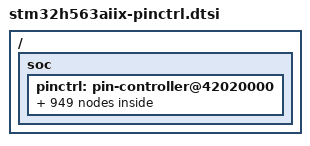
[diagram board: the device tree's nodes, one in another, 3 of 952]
/*
 * NOTE: Autogenerated file using genpinctrl.py
 *
 * SPDX-License-Identifier: Apache-2.0
 */

#include <zephyr/dt-bindings/pinctrl/stm32-pinctrl.h>

/ {
	soc {
		pinctrl: pin-controller@42020000 {

			/* ADC_IN / ADC_INN / ADC_INP */

			/omit-if-no-ref/ adc1_inn1_pa0: adc1_inn1_pa0 {
				pinmux = <STM32_PINMUX('A', 0, ANALOG)>;
			};

			/omit-if-no-ref/ adc1_inp0_pa0: adc1_inp0_pa0 {
				pinmux = <STM32_PINMUX('A', 0, ANALOG)>;
			};

			/omit-if-no-ref/ adc1_inp1_pa1: adc1_inp1_pa1 {
				pinmux = <STM32_PINMUX('A', 1, ANALOG)>;
			};

			/omit-if-no-ref/ adc1_inp14_pa2: adc1_inp14_pa2 {
				pinmux = <STM32_PINMUX('A', 2, ANALOG)>;
			};

			/omit-if-no-ref/ adc1_inp15_pa3: adc1_inp15_pa3 {
				pinmux = <STM32_PINMUX('A', 3, ANALOG)>;
			};

			/omit-if-no-ref/ adc1_inp18_pa4: adc1_inp18_pa4 {
				pinmux = <STM32_PINMUX('A', 4, ANALOG)>;
			};

			/omit-if-no-ref/ adc1_inn18_pa5: adc1_inn18_pa5 {
				pinmux = <STM32_PINMUX('A', 5, ANALOG)>;
			};

			/omit-if-no-ref/ adc1_inp19_pa5: adc1_inp19_pa5 {
				pinmux = <STM32_PINMUX('A', 5, ANALOG)>;
			};

			/omit-if-no-ref/ adc1_inp3_pa6: adc1_inp3_pa6 {
				pinmux = <STM32_PINMUX('A', 6, ANALOG)>;
			};

			/omit-if-no-ref/ adc1_inn3_pa7: adc1_inn3_pa7 {
				pinmux = <STM32_PINMUX('A', 7, ANALOG)>;
			};

			/omit-if-no-ref/ adc1_inp7_pa7: adc1_inp7_pa7 {
				pinmux = <STM32_PINMUX('A', 7, ANALOG)>;
			};

			/omit-if-no-ref/ adc1_inn5_pb0: adc1_inn5_pb0 {
				pinmux = <STM32_PINMUX('B', 0, ANALOG)>;
			};

			/omit-if-no-ref/ adc1_inp9_pb0: adc1_inp9_pb0 {
				pinmux = <STM32_PINMUX('B', 0, ANALOG)>;
			};

			/omit-if-no-ref/ adc1_inp5_pb1: adc1_inp5_pb1 {
				pinmux = <STM32_PINMUX('B', 1, ANALOG)>;
			};

			/omit-if-no-ref/ adc1_inp10_pc0: adc1_inp10_pc0 {
				pinmux = <STM32_PINMUX('C', 0, ANALOG)>;
			};

			/omit-if-no-ref/ adc1_inn10_pc1: adc1_inn10_pc1 {
				pinmux = <STM32_PINMUX('C', 1, ANALOG)>;
			};

			/omit-if-no-ref/ adc1_inp11_pc1: adc1_inp11_pc1 {
				pinmux = <STM32_PINMUX('C', 1, ANALOG)>;
			};

			/omit-if-no-ref/ adc1_inn11_pc2: adc1_inn11_pc2 {
				pinmux = <STM32_PINMUX('C', 2, ANALOG)>;
			};

			/omit-if-no-ref/ adc1_inp12_pc2: adc1_inp12_pc2 {
				pinmux = <STM32_PINMUX('C', 2, ANALOG)>;
			};

			/omit-if-no-ref/ adc1_inn12_pc3: adc1_inn12_pc3 {
				pinmux = <STM32_PINMUX('C', 3, ANALOG)>;
			};

			/omit-if-no-ref/ adc1_inp13_pc3: adc1_inp13_pc3 {
				pinmux = <STM32_PINMUX('C', 3, ANALOG)>;
			};

			/omit-if-no-ref/ adc1_inp4_pc4: adc1_inp4_pc4 {
				pinmux = <STM32_PINMUX('C', 4, ANALOG)>;
			};

			/omit-if-no-ref/ adc1_inn4_pc5: adc1_inn4_pc5 {
				pinmux = <STM32_PINMUX('C', 5, ANALOG)>;
			};

			/omit-if-no-ref/ adc1_inp8_pc5: adc1_inp8_pc5 {
				pinmux = <STM32_PINMUX('C', 5, ANALOG)>;
			};

			/omit-if-no-ref/ adc1_inp2_pf11: adc1_inp2_pf11 {
				pinmux = <STM32_PINMUX('F', 11, ANALOG)>;
			};

			/omit-if-no-ref/ adc1_inn2_pf12: adc1_inn2_pf12 {
				pinmux = <STM32_PINMUX('F', 12, ANALOG)>;
			};

			/omit-if-no-ref/ adc1_inp6_pf12: adc1_inp6_pf12 {
				pinmux = <STM32_PINMUX('F', 12, ANALOG)>;
			};

			/omit-if-no-ref/ adc2_inn1_pa0: adc2_inn1_pa0 {
				pinmux = <STM32_PINMUX('A', 0, ANALOG)>;
			};

			/omit-if-no-ref/ adc2_inp0_pa0: adc2_inp0_pa0 {
				pinmux = <STM32_PINMUX('A', 0, ANALOG)>;
			};

			/omit-if-no-ref/ adc2_inp1_pa1: adc2_inp1_pa1 {
				pinmux = <STM32_PINMUX('A', 1, ANALOG)>;
			};

			/omit-if-no-ref/ adc2_inp14_pa2: adc2_inp14_pa2 {
				pinmux = <STM32_PINMUX('A', 2, ANALOG)>;
			};

			/omit-if-no-ref/ adc2_inp15_pa3: adc2_inp15_pa3 {
				pinmux = <STM32_PINMUX('A', 3, ANALOG)>;
			};

			/omit-if-no-ref/ adc2_inp18_pa4: adc2_inp18_pa4 {
				pinmux = <STM32_PINMUX('A', 4, ANALOG)>;
			};

			/omit-if-no-ref/ adc2_inn18_pa5: adc2_inn18_pa5 {
				pinmux = <STM32_PINMUX('A', 5, ANALOG)>;
			};

			/omit-if-no-ref/ adc2_inp19_pa5: adc2_inp19_pa5 {
				pinmux = <STM32_PINMUX('A', 5, ANALOG)>;
			};

			/omit-if-no-ref/ adc2_inp3_pa6: adc2_inp3_pa6 {
				pinmux = <STM32_PINMUX('A', 6, ANALOG)>;
			};

			/omit-if-no-ref/ adc2_inn3_pa7: adc2_inn3_pa7 {
				pinmux = <STM32_PINMUX('A', 7, ANALOG)>;
			};

			/omit-if-no-ref/ adc2_inp7_pa7: adc2_inp7_pa7 {
				pinmux = <STM32_PINMUX('A', 7, ANALOG)>;
			};

			/omit-if-no-ref/ adc2_inn5_pb0: adc2_inn5_pb0 {
				pinmux = <STM32_PINMUX('B', 0, ANALOG)>;
			};

			/omit-if-no-ref/ adc2_inp9_pb0: adc2_inp9_pb0 {
				pinmux = <STM32_PINMUX('B', 0, ANALOG)>;
			};

			/omit-if-no-ref/ adc2_inp5_pb1: adc2_inp5_pb1 {
				pinmux = <STM32_PINMUX('B', 1, ANALOG)>;
			};

			/omit-if-no-ref/ adc2_inp10_pc0: adc2_inp10_pc0 {
				pinmux = <STM32_PINMUX('C', 0, ANALOG)>;
			};

			/omit-if-no-ref/ adc2_inn10_pc1: adc2_inn10_pc1 {
				pinmux = <STM32_PINMUX('C', 1, ANALOG)>;
			};

			/omit-if-no-ref/ adc2_inp11_pc1: adc2_inp11_pc1 {
				pinmux = <STM32_PINMUX('C', 1, ANALOG)>;
			};

			/omit-if-no-ref/ adc2_inn11_pc2: adc2_inn11_pc2 {
				pinmux = <STM32_PINMUX('C', 2, ANALOG)>;
			};

			/omit-if-no-ref/ adc2_inp12_pc2: adc2_inp12_pc2 {
				pinmux = <STM32_PINMUX('C', 2, ANALOG)>;
			};

			/omit-if-no-ref/ adc2_inn12_pc3: adc2_inn12_pc3 {
				pinmux = <STM32_PINMUX('C', 3, ANALOG)>;
			};

			/omit-if-no-ref/ adc2_inp13_pc3: adc2_inp13_pc3 {
				pinmux = <STM32_PINMUX('C', 3, ANALOG)>;
			};

			/omit-if-no-ref/ adc2_inp4_pc4: adc2_inp4_pc4 {
				pinmux = <STM32_PINMUX('C', 4, ANALOG)>;
			};

			/omit-if-no-ref/ adc2_inn4_pc5: adc2_inn4_pc5 {
				pinmux = <STM32_PINMUX('C', 5, ANALOG)>;
			};

			/omit-if-no-ref/ adc2_inp8_pc5: adc2_inp8_pc5 {
				pinmux = <STM32_PINMUX('C', 5, ANALOG)>;
			};

			/omit-if-no-ref/ adc2_inp2_pf13: adc2_inp2_pf13 {
				pinmux = <STM32_PINMUX('F', 13, ANALOG)>;
			};

			/omit-if-no-ref/ adc2_inn2_pf14: adc2_inn2_pf14 {
				pinmux = <STM32_PINMUX('F', 14, ANALOG)>;
			};

			/omit-if-no-ref/ adc2_inp6_pf14: adc2_inp6_pf14 {
				pinmux = <STM32_PINMUX('F', 14, ANALOG)>;
			};

			/* Analog */

			/omit-if-no-ref/ analog_pa0: analog_pa0 {
				pinmux = <STM32_PINMUX('A', 0, ANALOG)>;
			};

			/omit-if-no-ref/ analog_pa1: analog_pa1 {
				pinmux = <STM32_PINMUX('A', 1, ANALOG)>;
			};

			/omit-if-no-ref/ analog_pa2: analog_pa2 {
				pinmux = <STM32_PINMUX('A', 2, ANALOG)>;
			};

			/omit-if-no-ref/ analog_pa3: analog_pa3 {
				pinmux = <STM32_PINMUX('A', 3, ANALOG)>;
			};

			/omit-if-no-ref/ analog_pa4: analog_pa4 {
				pinmux = <STM32_PINMUX('A', 4, ANALOG)>;
			};

			/omit-if-no-ref/ analog_pa5: analog_pa5 {
				pinmux = <STM32_PINMUX('A', 5, ANALOG)>;
			};

			/omit-if-no-ref/ analog_pa6: analog_pa6 {
				pinmux = <STM32_PINMUX('A', 6, ANALOG)>;
			};

			/omit-if-no-ref/ analog_pa7: analog_pa7 {
				pinmux = <STM32_PINMUX('A', 7, ANALOG)>;
			};

			/omit-if-no-ref/ analog_pa8: analog_pa8 {
				pinmux = <STM32_PINMUX('A', 8, ANALOG)>;
			};

			/omit-if-no-ref/ analog_pa9: analog_pa9 {
				pinmux = <STM32_PINMUX('A', 9, ANALOG)>;
			};

			/omit-if-no-ref/ analog_pa10: analog_pa10 {
				pinmux = <STM32_PINMUX('A', 10, ANALOG)>;
			};

			/omit-if-no-ref/ analog_pa11: analog_pa11 {
				pinmux = <STM32_PINMUX('A', 11, ANALOG)>;
			};

			/omit-if-no-ref/ analog_pa12: analog_pa12 {
				pinmux = <STM32_PINMUX('A', 12, ANALOG)>;
			};

			/omit-if-no-ref/ analog_pa13: analog_pa13 {
				pinmux = <STM32_PINMUX('A', 13, ANALOG)>;
			};

			/omit-if-no-ref/ analog_pa14: analog_pa14 {
				pinmux = <STM32_PINMUX('A', 14, ANALOG)>;
			};

			/omit-if-no-ref/ analog_pa15: analog_pa15 {
				pinmux = <STM32_PINMUX('A', 15, ANALOG)>;
			};

			/omit-if-no-ref/ analog_pb0: analog_pb0 {
				pinmux = <STM32_PINMUX('B', 0, ANALOG)>;
			};

			/omit-if-no-ref/ analog_pb1: analog_pb1 {
				pinmux = <STM32_PINMUX('B', 1, ANALOG)>;
			};

			/omit-if-no-ref/ analog_pb2: analog_pb2 {
				pinmux = <STM32_PINMUX('B', 2, ANALOG)>;
			};

			/omit-if-no-ref/ analog_pb3: analog_pb3 {
				pinmux = <STM32_PINMUX('B', 3, ANALOG)>;
			};

			/omit-if-no-ref/ analog_pb4: analog_pb4 {
				pinmux = <STM32_PINMUX('B', 4, ANALOG)>;
			};

			/omit-if-no-ref/ analog_pb5: analog_pb5 {
				pinmux = <STM32_PINMUX('B', 5, ANALOG)>;
			};

			/omit-if-no-ref/ analog_pb6: analog_pb6 {
				pinmux = <STM32_PINMUX('B', 6, ANALOG)>;
			};

			/omit-if-no-ref/ analog_pb7: analog_pb7 {
				pinmux = <STM32_PINMUX('B', 7, ANALOG)>;
			};

			/omit-if-no-ref/ analog_pb8: analog_pb8 {
				pinmux = <STM32_PINMUX('B', 8, ANALOG)>;
			};

			/omit-if-no-ref/ analog_pb9: analog_pb9 {
				pinmux = <STM32_PINMUX('B', 9, ANALOG)>;
			};

			/omit-if-no-ref/ analog_pb10: analog_pb10 {
				pinmux = <STM32_PINMUX('B', 10, ANALOG)>;
			};

			/omit-if-no-ref/ analog_pb11: analog_pb11 {
				pinmux = <STM32_PINMUX('B', 11, ANALOG)>;
			};

			/omit-if-no-ref/ analog_pb12: analog_pb12 {
				pinmux = <STM32_PINMUX('B', 12, ANALOG)>;
			};

			/omit-if-no-ref/ analog_pb13: analog_pb13 {
				pinmux = <STM32_PINMUX('B', 13, ANALOG)>;
			};

			/omit-if-no-ref/ analog_pb14: analog_pb14 {
				pinmux = <STM32_PINMUX('B', 14, ANALOG)>;
			};

			/omit-if-no-ref/ analog_pb15: analog_pb15 {
				pinmux = <STM32_PINMUX('B', 15, ANALOG)>;
			};

			/omit-if-no-ref/ analog_pc0: analog_pc0 {
				pinmux = <STM32_PINMUX('C', 0, ANALOG)>;
			};

			/omit-if-no-ref/ analog_pc1: analog_pc1 {
				pinmux = <STM32_PINMUX('C', 1, ANALOG)>;
			};

			/omit-if-no-ref/ analog_pc2: analog_pc2 {
				pinmux = <STM32_PINMUX('C', 2, ANALOG)>;
			};

			/omit-if-no-ref/ analog_pc3: analog_pc3 {
				pinmux = <STM32_PINMUX('C', 3, ANALOG)>;
			};

			/omit-if-no-ref/ analog_pc4: analog_pc4 {
				pinmux = <STM32_PINMUX('C', 4, ANALOG)>;
			};

			/omit-if-no-ref/ analog_pc5: analog_pc5 {
				pinmux = <STM32_PINMUX('C', 5, ANALOG)>;
			};

			/omit-if-no-ref/ analog_pc6: analog_pc6 {
				pinmux = <STM32_PINMUX('C', 6, ANALOG)>;
			};

			/omit-if-no-ref/ analog_pc7: analog_pc7 {
				pinmux = <STM32_PINMUX('C', 7, ANALOG)>;
			};

			/omit-if-no-ref/ analog_pc8: analog_pc8 {
				pinmux = <STM32_PINMUX('C', 8, ANALOG)>;
			};

			/omit-if-no-ref/ analog_pc9: analog_pc9 {
				pinmux = <STM32_PINMUX('C', 9, ANALOG)>;
			};

			/omit-if-no-ref/ analog_pc10: analog_pc10 {
				pinmux = <STM32_PINMUX('C', 10, ANALOG)>;
			};

			/omit-if-no-ref/ analog_pc11: analog_pc11 {
				pinmux = <STM32_PINMUX('C', 11, ANALOG)>;
			};

			/omit-if-no-ref/ analog_pc12: analog_pc12 {
				pinmux = <STM32_PINMUX('C', 12, ANALOG)>;
			};

			/omit-if-no-ref/ analog_pc13: analog_pc13 {
				pinmux = <STM32_PINMUX('C', 13, ANALOG)>;
			};

			/omit-if-no-ref/ analog_pc14: analog_pc14 {
				pinmux = <STM32_PINMUX('C', 14, ANALOG)>;
			};

			/omit-if-no-ref/ analog_pc15: analog_pc15 {
				pinmux = <STM32_PINMUX('C', 15, ANALOG)>;
			};

			/omit-if-no-ref/ analog_pd0: analog_pd0 {
				pinmux = <STM32_PINMUX('D', 0, ANALOG)>;
			};

			/omit-if-no-ref/ analog_pd1: analog_pd1 {
				pinmux = <STM32_PINMUX('D', 1, ANALOG)>;
			};

			/omit-if-no-ref/ analog_pd2: analog_pd2 {
				pinmux = <STM32_PINMUX('D', 2, ANALOG)>;
			};

			/omit-if-no-ref/ analog_pd3: analog_pd3 {
				pinmux = <STM32_PINMUX('D', 3, ANALOG)>;
			};

			/omit-if-no-ref/ analog_pd4: analog_pd4 {
				pinmux = <STM32_PINMUX('D', 4, ANALOG)>;
			};

			/omit-if-no-ref/ analog_pd5: analog_pd5 {
				pinmux = <STM32_PINMUX('D', 5, ANALOG)>;
			};

			/omit-if-no-ref/ analog_pd6: analog_pd6 {
				pinmux = <STM32_PINMUX('D', 6, ANALOG)>;
			};

			/omit-if-no-ref/ analog_pd7: analog_pd7 {
				pinmux = <STM32_PINMUX('D', 7, ANALOG)>;
			};

			/omit-if-no-ref/ analog_pd8: analog_pd8 {
				pinmux = <STM32_PINMUX('D', 8, ANALOG)>;
			};

			/omit-if-no-ref/ analog_pd9: analog_pd9 {
				pinmux = <STM32_PINMUX('D', 9, ANALOG)>;
			};

			/omit-if-no-ref/ analog_pd10: analog_pd10 {
				pinmux = <STM32_PINMUX('D', 10, ANALOG)>;
			};

			/omit-if-no-ref/ analog_pd11: analog_pd11 {
				pinmux = <STM32_PINMUX('D', 11, ANALOG)>;
			};

			/omit-if-no-ref/ analog_pd12: analog_pd12 {
				pinmux = <STM32_PINMUX('D', 12, ANALOG)>;
			};

			/omit-if-no-ref/ analog_pd13: analog_pd13 {
				pinmux = <STM32_PINMUX('D', 13, ANALOG)>;
			};

			/omit-if-no-ref/ analog_pd14: analog_pd14 {
				pinmux = <STM32_PINMUX('D', 14, ANALOG)>;
			};

			/omit-if-no-ref/ analog_pd15: analog_pd15 {
				pinmux = <STM32_PINMUX('D', 15, ANALOG)>;
			};

			/omit-if-no-ref/ analog_pe0: analog_pe0 {
				pinmux = <STM32_PINMUX('E', 0, ANALOG)>;
			};

			/omit-if-no-ref/ analog_pe1: analog_pe1 {
				pinmux = <STM32_PINMUX('E', 1, ANALOG)>;
			};

			/omit-if-no-ref/ analog_pe2: analog_pe2 {
				pinmux = <STM32_PINMUX('E', 2, ANALOG)>;
			};

			/omit-if-no-ref/ analog_pe3: analog_pe3 {
				pinmux = <STM32_PINMUX('E', 3, ANALOG)>;
			};

			/omit-if-no-ref/ analog_pe4: analog_pe4 {
				pinmux = <STM32_PINMUX('E', 4, ANALOG)>;
			};

			/omit-if-no-ref/ analog_pe5: analog_pe5 {
				pinmux = <STM32_PINMUX('E', 5, ANALOG)>;
			};

			/omit-if-no-ref/ analog_pe6: analog_pe6 {
				pinmux = <STM32_PINMUX('E', 6, ANALOG)>;
			};

			/omit-if-no-ref/ analog_pe7: analog_pe7 {
				pinmux = <STM32_PINMUX('E', 7, ANALOG)>;
			};

			/omit-if-no-ref/ analog_pe8: analog_pe8 {
				pinmux = <STM32_PINMUX('E', 8, ANALOG)>;
			};

			/omit-if-no-ref/ analog_pe9: analog_pe9 {
				pinmux = <STM32_PINMUX('E', 9, ANALOG)>;
			};

			/omit-if-no-ref/ analog_pe10: analog_pe10 {
				pinmux = <STM32_PINMUX('E', 10, ANALOG)>;
			};

			/omit-if-no-ref/ analog_pe11: analog_pe11 {
				pinmux = <STM32_PINMUX('E', 11, ANALOG)>;
			};

			/omit-if-no-ref/ analog_pe12: analog_pe12 {
				pinmux = <STM32_PINMUX('E', 12, ANALOG)>;
			};

			/omit-if-no-ref/ analog_pe13: analog_pe13 {
				pinmux = <STM32_PINMUX('E', 13, ANALOG)>;
			};

			/omit-if-no-ref/ analog_pe14: analog_pe14 {
				pinmux = <STM32_PINMUX('E', 14, ANALOG)>;
			};

			/omit-if-no-ref/ analog_pe15: analog_pe15 {
				pinmux = <STM32_PINMUX('E', 15, ANALOG)>;
			};

			/omit-if-no-ref/ analog_pf0: analog_pf0 {
				pinmux = <STM32_PINMUX('F', 0, ANALOG)>;
			};

			/omit-if-no-ref/ analog_pf1: analog_pf1 {
				pinmux = <STM32_PINMUX('F', 1, ANALOG)>;
			};

			/omit-if-no-ref/ analog_pf2: analog_pf2 {
				pinmux = <STM32_PINMUX('F', 2, ANALOG)>;
			};

			/omit-if-no-ref/ analog_pf3: analog_pf3 {
				pinmux = <STM32_PINMUX('F', 3, ANALOG)>;
			};

			/omit-if-no-ref/ analog_pf4: analog_pf4 {
				pinmux = <STM32_PINMUX('F', 4, ANALOG)>;
			};

			/omit-if-no-ref/ analog_pf5: analog_pf5 {
				pinmux = <STM32_PINMUX('F', 5, ANALOG)>;
			};

			/omit-if-no-ref/ analog_pf6: analog_pf6 {
				pinmux = <STM32_PINMUX('F', 6, ANALOG)>;
			};

			/omit-if-no-ref/ analog_pf7: analog_pf7 {
				pinmux = <STM32_PINMUX('F', 7, ANALOG)>;
			};

			/omit-if-no-ref/ analog_pf8: analog_pf8 {
				pinmux = <STM32_PINMUX('F', 8, ANALOG)>;
			};

			/omit-if-no-ref/ analog_pf9: analog_pf9 {
				pinmux = <STM32_PINMUX('F', 9, ANALOG)>;
			};

			/omit-if-no-ref/ analog_pf10: analog_pf10 {
				pinmux = <STM32_PINMUX('F', 10, ANALOG)>;
			};

			/omit-if-no-ref/ analog_pf11: analog_pf11 {
				pinmux = <STM32_PINMUX('F', 11, ANALOG)>;
			};

			/omit-if-no-ref/ analog_pf12: analog_pf12 {
				pinmux = <STM32_PINMUX('F', 12, ANALOG)>;
			};

			/omit-if-no-ref/ analog_pf13: analog_pf13 {
				pinmux = <STM32_PINMUX('F', 13, ANALOG)>;
			};

			/omit-if-no-ref/ analog_pf14: analog_pf14 {
				pinmux = <STM32_PINMUX('F', 14, ANALOG)>;
			};

			/omit-if-no-ref/ analog_pf15: analog_pf15 {
				pinmux = <STM32_PINMUX('F', 15, ANALOG)>;
			};

			/omit-if-no-ref/ analog_pg0: analog_pg0 {
				pinmux = <STM32_PINMUX('G', 0, ANALOG)>;
			};

			/omit-if-no-ref/ analog_pg1: analog_pg1 {
				pinmux = <STM32_PINMUX('G', 1, ANALOG)>;
			};

			/omit-if-no-ref/ analog_pg2: analog_pg2 {
				pinmux = <STM32_PINMUX('G', 2, ANALOG)>;
			};

			/omit-if-no-ref/ analog_pg3: analog_pg3 {
				pinmux = <STM32_PINMUX('G', 3, ANALOG)>;
			};

			/omit-if-no-ref/ analog_pg4: analog_pg4 {
				pinmux = <STM32_PINMUX('G', 4, ANALOG)>;
			};

			/omit-if-no-ref/ analog_pg5: analog_pg5 {
				pinmux = <STM32_PINMUX('G', 5, ANALOG)>;
			};

			/omit-if-no-ref/ analog_pg6: analog_pg6 {
				pinmux = <STM32_PINMUX('G', 6, ANALOG)>;
			};

			/omit-if-no-ref/ analog_pg7: analog_pg7 {
				pinmux = <STM32_PINMUX('G', 7, ANALOG)>;
			};

			/omit-if-no-ref/ analog_pg8: analog_pg8 {
				pinmux = <STM32_PINMUX('G', 8, ANALOG)>;
			};

			/omit-if-no-ref/ analog_pg9: analog_pg9 {
				pinmux = <STM32_PINMUX('G', 9, ANALOG)>;
			};

			/omit-if-no-ref/ analog_pg10: analog_pg10 {
				pinmux = <STM32_PINMUX('G', 10, ANALOG)>;
			};

			/omit-if-no-ref/ analog_pg11: analog_pg11 {
				pinmux = <STM32_PINMUX('G', 11, ANALOG)>;
			};

			/omit-if-no-ref/ analog_pg12: analog_pg12 {
				pinmux = <STM32_PINMUX('G', 12, ANALOG)>;
			};

			/omit-if-no-ref/ analog_pg13: analog_pg13 {
				pinmux = <STM32_PINMUX('G', 13, ANALOG)>;
			};

			/omit-if-no-ref/ analog_pg14: analog_pg14 {
				pinmux = <STM32_PINMUX('G', 14, ANALOG)>;
			};

			/omit-if-no-ref/ analog_pg15: analog_pg15 {
				pinmux = <STM32_PINMUX('G', 15, ANALOG)>;
			};

			/omit-if-no-ref/ analog_ph0: analog_ph0 {
				pinmux = <STM32_PINMUX('H', 0, ANALOG)>;
			};

			/omit-if-no-ref/ analog_ph1: analog_ph1 {
				pinmux = <STM32_PINMUX('H', 1, ANALOG)>;
			};

			/omit-if-no-ref/ analog_ph2: analog_ph2 {
				pinmux = <STM32_PINMUX('H', 2, ANALOG)>;
			};

			/omit-if-no-ref/ analog_ph3: analog_ph3 {
				pinmux = <STM32_PINMUX('H', 3, ANALOG)>;
			};

			/omit-if-no-ref/ analog_ph4: analog_ph4 {
				pinmux = <STM32_PINMUX('H', 4, ANALOG)>;
			};

			/omit-if-no-ref/ analog_ph5: analog_ph5 {
				pinmux = <STM32_PINMUX('H', 5, ANALOG)>;
			};

			/omit-if-no-ref/ analog_ph6: analog_ph6 {
				pinmux = <STM32_PINMUX('H', 6, ANALOG)>;
			};

			/omit-if-no-ref/ analog_ph7: analog_ph7 {
				pinmux = <STM32_PINMUX('H', 7, ANALOG)>;
			};

			/omit-if-no-ref/ analog_ph8: analog_ph8 {
				pinmux = <STM32_PINMUX('H', 8, ANALOG)>;
			};

			/omit-if-no-ref/ analog_ph10: analog_ph10 {
				pinmux = <STM32_PINMUX('H', 10, ANALOG)>;
			};

			/omit-if-no-ref/ analog_ph11: analog_ph11 {
				pinmux = <STM32_PINMUX('H', 11, ANALOG)>;
			};

			/omit-if-no-ref/ analog_ph12: analog_ph12 {
				pinmux = <STM32_PINMUX('H', 12, ANALOG)>;
			};

			/omit-if-no-ref/ analog_ph13: analog_ph13 {
				pinmux = <STM32_PINMUX('H', 13, ANALOG)>;
			};

			/omit-if-no-ref/ analog_ph14: analog_ph14 {
				pinmux = <STM32_PINMUX('H', 14, ANALOG)>;
			};

			/omit-if-no-ref/ analog_ph15: analog_ph15 {
				pinmux = <STM32_PINMUX('H', 15, ANALOG)>;
			};

			/omit-if-no-ref/ analog_pi0: analog_pi0 {
				pinmux = <STM32_PINMUX('I', 0, ANALOG)>;
			};

			/omit-if-no-ref/ analog_pi1: analog_pi1 {
				pinmux = <STM32_PINMUX('I', 1, ANALOG)>;
			};

			/omit-if-no-ref/ analog_pi2: analog_pi2 {
				pinmux = <STM32_PINMUX('I', 2, ANALOG)>;
			};

			/omit-if-no-ref/ analog_pi3: analog_pi3 {
				pinmux = <STM32_PINMUX('I', 3, ANALOG)>;
			};

			/omit-if-no-ref/ analog_pi4: analog_pi4 {
				pinmux = <STM32_PINMUX('I', 4, ANALOG)>;
			};

			/omit-if-no-ref/ analog_pi6: analog_pi6 {
				pinmux = <STM32_PINMUX('I', 6, ANALOG)>;
			};

			/omit-if-no-ref/ analog_pi7: analog_pi7 {
				pinmux = <STM32_PINMUX('I', 7, ANALOG)>;
			};

			/omit-if-no-ref/ analog_pi8: analog_pi8 {
				pinmux = <STM32_PINMUX('I', 8, ANALOG)>;
			};

			/omit-if-no-ref/ analog_pi11: analog_pi11 {
				pinmux = <STM32_PINMUX('I', 11, ANALOG)>;
			};

			/* DAC_OUT */

			/omit-if-no-ref/ dac1_out1_pa4: dac1_out1_pa4 {
				pinmux = <STM32_PINMUX('A', 4, ANALOG)>;
			};

			/omit-if-no-ref/ dac1_out2_pa5: dac1_out2_pa5 {
				pinmux = <STM32_PINMUX('A', 5, ANALOG)>;
			};

			/* DCMI */

			/omit-if-no-ref/ dcmi_hsync_pa4: dcmi_hsync_pa4 {
				pinmux = <STM32_PINMUX('A', 4, AF13)>;
				slew-rate = "very-high-speed";
			};

			/omit-if-no-ref/ dcmi_pixclk_pa6: dcmi_pixclk_pa6 {
				pinmux = <STM32_PINMUX('A', 6, AF13)>;
				slew-rate = "very-high-speed";
			};

			/omit-if-no-ref/ dcmi_d3_pa8: dcmi_d3_pa8 {
				pinmux = <STM32_PINMUX('A', 8, AF13)>;
				slew-rate = "very-high-speed";
			};

			/omit-if-no-ref/ dcmi_d0_pa9: dcmi_d0_pa9 {
				pinmux = <STM32_PINMUX('A', 9, AF13)>;
				slew-rate = "very-high-speed";
			};

			/omit-if-no-ref/ dcmi_d1_pa10: dcmi_d1_pa10 {
				pinmux = <STM32_PINMUX('A', 10, AF13)>;
				slew-rate = "very-high-speed";
			};

			/omit-if-no-ref/ dcmi_d11_pa15: dcmi_d11_pa15 {
				pinmux = <STM32_PINMUX('A', 15, AF13)>;
				slew-rate = "very-high-speed";
			};

			/omit-if-no-ref/ dcmi_d7_pb4: dcmi_d7_pb4 {
				pinmux = <STM32_PINMUX('B', 4, AF13)>;
				slew-rate = "very-high-speed";
			};

			/omit-if-no-ref/ dcmi_d10_pb5: dcmi_d10_pb5 {
				pinmux = <STM32_PINMUX('B', 5, AF13)>;
				slew-rate = "very-high-speed";
			};

			/omit-if-no-ref/ dcmi_d5_pb6: dcmi_d5_pb6 {
				pinmux = <STM32_PINMUX('B', 6, AF13)>;
				slew-rate = "very-high-speed";
			};

			/omit-if-no-ref/ dcmi_vsync_pb7: dcmi_vsync_pb7 {
				pinmux = <STM32_PINMUX('B', 7, AF13)>;
				slew-rate = "very-high-speed";
			};

			/omit-if-no-ref/ dcmi_d6_pb8: dcmi_d6_pb8 {
				pinmux = <STM32_PINMUX('B', 8, AF13)>;
				slew-rate = "very-high-speed";
			};

			/omit-if-no-ref/ dcmi_d7_pb9: dcmi_d7_pb9 {
				pinmux = <STM32_PINMUX('B', 9, AF13)>;
				slew-rate = "very-high-speed";
			};

			/omit-if-no-ref/ dcmi_d2_pb15: dcmi_d2_pb15 {
				pinmux = <STM32_PINMUX('B', 15, AF13)>;
				slew-rate = "very-high-speed";
			};

			/omit-if-no-ref/ dcmi_d0_pc6: dcmi_d0_pc6 {
				pinmux = <STM32_PINMUX('C', 6, AF13)>;
				slew-rate = "very-high-speed";
			};

			/omit-if-no-ref/ dcmi_d1_pc7: dcmi_d1_pc7 {
				pinmux = <STM32_PINMUX('C', 7, AF13)>;
				slew-rate = "very-high-speed";
			};

			/omit-if-no-ref/ dcmi_d2_pc8: dcmi_d2_pc8 {
				pinmux = <STM32_PINMUX('C', 8, AF13)>;
				slew-rate = "very-high-speed";
			};

			/omit-if-no-ref/ dcmi_d3_pc9: dcmi_d3_pc9 {
				pinmux = <STM32_PINMUX('C', 9, AF13)>;
				slew-rate = "very-high-speed";
			};

			/omit-if-no-ref/ dcmi_d8_pc10: dcmi_d8_pc10 {
				pinmux = <STM32_PINMUX('C', 10, AF13)>;
				slew-rate = "very-high-speed";
			};

			/omit-if-no-ref/ dcmi_d4_pc11: dcmi_d4_pc11 {
				pinmux = <STM32_PINMUX('C', 11, AF13)>;
				slew-rate = "very-high-speed";
			};

			/omit-if-no-ref/ dcmi_d9_pc12: dcmi_d9_pc12 {
				pinmux = <STM32_PINMUX('C', 12, AF13)>;
				slew-rate = "very-high-speed";
			};

			/omit-if-no-ref/ dcmi_d11_pd2: dcmi_d11_pd2 {
				pinmux = <STM32_PINMUX('D', 2, AF13)>;
				slew-rate = "very-high-speed";
			};

			/omit-if-no-ref/ dcmi_d5_pd3: dcmi_d5_pd3 {
				pinmux = <STM32_PINMUX('D', 3, AF13)>;
				slew-rate = "very-high-speed";
			};

			/omit-if-no-ref/ dcmi_d10_pd6: dcmi_d10_pd6 {
				pinmux = <STM32_PINMUX('D', 6, AF13)>;
				slew-rate = "very-high-speed";
			};

			/omit-if-no-ref/ dcmi_d12_pd12: dcmi_d12_pd12 {
				pinmux = <STM32_PINMUX('D', 12, AF13)>;
				slew-rate = "very-high-speed";
			};

			/omit-if-no-ref/ dcmi_d13_pd13: dcmi_d13_pd13 {
				pinmux = <STM32_PINMUX('D', 13, AF13)>;
				slew-rate = "very-high-speed";
			};

			/omit-if-no-ref/ dcmi_d2_pe0: dcmi_d2_pe0 {
				pinmux = <STM32_PINMUX('E', 0, AF13)>;
				slew-rate = "very-high-speed";
			};

			/omit-if-no-ref/ dcmi_d3_pe1: dcmi_d3_pe1 {
				pinmux = <STM32_PINMUX('E', 1, AF13)>;
				slew-rate = "very-high-speed";
			};

			/omit-if-no-ref/ dcmi_d3_pe2: dcmi_d3_pe2 {
				pinmux = <STM32_PINMUX('E', 2, AF13)>;
				slew-rate = "very-high-speed";
			};

			/omit-if-no-ref/ dcmi_d4_pe4: dcmi_d4_pe4 {
				pinmux = <STM32_PINMUX('E', 4, AF13)>;
				slew-rate = "very-high-speed";
			};

			/omit-if-no-ref/ dcmi_d6_pe5: dcmi_d6_pe5 {
				pinmux = <STM32_PINMUX('E', 5, AF13)>;
				slew-rate = "very-high-speed";
			};

			/omit-if-no-ref/ dcmi_d7_pe6: dcmi_d7_pe6 {
				pinmux = <STM32_PINMUX('E', 6, AF13)>;
				slew-rate = "very-high-speed";
			};

			/omit-if-no-ref/ dcmi_d11_pf10: dcmi_d11_pf10 {
				pinmux = <STM32_PINMUX('F', 10, AF13)>;
				slew-rate = "very-high-speed";
			};

			/omit-if-no-ref/ dcmi_d12_pf11: dcmi_d12_pf11 {
				pinmux = <STM32_PINMUX('F', 11, AF13)>;
				slew-rate = "very-high-speed";
			};

			/omit-if-no-ref/ dcmi_d12_pg6: dcmi_d12_pg6 {
				pinmux = <STM32_PINMUX('G', 6, AF13)>;
				slew-rate = "very-high-speed";
			};

			/omit-if-no-ref/ dcmi_d13_pg7: dcmi_d13_pg7 {
				pinmux = <STM32_PINMUX('G', 7, AF13)>;
				slew-rate = "very-high-speed";
			};

			/omit-if-no-ref/ dcmi_vsync_pg9: dcmi_vsync_pg9 {
				pinmux = <STM32_PINMUX('G', 9, AF13)>;
				slew-rate = "very-high-speed";
			};

			/omit-if-no-ref/ dcmi_d2_pg10: dcmi_d2_pg10 {
				pinmux = <STM32_PINMUX('G', 10, AF13)>;
				slew-rate = "very-high-speed";
			};

			/omit-if-no-ref/ dcmi_d3_pg11: dcmi_d3_pg11 {
				pinmux = <STM32_PINMUX('G', 11, AF13)>;
				slew-rate = "very-high-speed";
			};

			/omit-if-no-ref/ dcmi_d11_pg12: dcmi_d11_pg12 {
				pinmux = <STM32_PINMUX('G', 12, AF13)>;
				slew-rate = "very-high-speed";
			};

			/omit-if-no-ref/ dcmi_d13_pg15: dcmi_d13_pg15 {
				pinmux = <STM32_PINMUX('G', 15, AF13)>;
				slew-rate = "very-high-speed";
			};

			/omit-if-no-ref/ dcmi_d8_ph6: dcmi_d8_ph6 {
				pinmux = <STM32_PINMUX('H', 6, AF13)>;
				slew-rate = "very-high-speed";
			};

			/omit-if-no-ref/ dcmi_d9_ph7: dcmi_d9_ph7 {
				pinmux = <STM32_PINMUX('H', 7, AF13)>;
				slew-rate = "very-high-speed";
			};

			/omit-if-no-ref/ dcmi_hsync_ph8: dcmi_hsync_ph8 {
				pinmux = <STM32_PINMUX('H', 8, AF13)>;
				slew-rate = "very-high-speed";
			};

			/omit-if-no-ref/ dcmi_d1_ph10: dcmi_d1_ph10 {
				pinmux = <STM32_PINMUX('H', 10, AF13)>;
				slew-rate = "very-high-speed";
			};

			/omit-if-no-ref/ dcmi_d2_ph11: dcmi_d2_ph11 {
				pinmux = <STM32_PINMUX('H', 11, AF13)>;
				slew-rate = "very-high-speed";
			};

			/omit-if-no-ref/ dcmi_d3_ph12: dcmi_d3_ph12 {
				pinmux = <STM32_PINMUX('H', 12, AF13)>;
				slew-rate = "very-high-speed";
			};

			/omit-if-no-ref/ dcmi_d3_ph13: dcmi_d3_ph13 {
				pinmux = <STM32_PINMUX('H', 13, AF13)>;
				slew-rate = "very-high-speed";
			};

			/omit-if-no-ref/ dcmi_d4_ph14: dcmi_d4_ph14 {
				pinmux = <STM32_PINMUX('H', 14, AF13)>;
				slew-rate = "very-high-speed";
			};

			/omit-if-no-ref/ dcmi_d11_ph15: dcmi_d11_ph15 {
				pinmux = <STM32_PINMUX('H', 15, AF13)>;
				slew-rate = "very-high-speed";
			};

			/omit-if-no-ref/ dcmi_d13_pi0: dcmi_d13_pi0 {
				pinmux = <STM32_PINMUX('I', 0, AF13)>;
				slew-rate = "very-high-speed";
			};

			/omit-if-no-ref/ dcmi_d8_pi1: dcmi_d8_pi1 {
				pinmux = <STM32_PINMUX('I', 1, AF13)>;
				slew-rate = "very-high-speed";
			};

			/omit-if-no-ref/ dcmi_d9_pi2: dcmi_d9_pi2 {
				pinmux = <STM32_PINMUX('I', 2, AF13)>;
				slew-rate = "very-high-speed";
			};

			/omit-if-no-ref/ dcmi_d10_pi3: dcmi_d10_pi3 {
				pinmux = <STM32_PINMUX('I', 3, AF13)>;
				slew-rate = "very-high-speed";
			};

			/omit-if-no-ref/ dcmi_d5_pi4: dcmi_d5_pi4 {
				pinmux = <STM32_PINMUX('I', 4, AF13)>;
				slew-rate = "very-high-speed";
			};

			/omit-if-no-ref/ dcmi_d6_pi6: dcmi_d6_pi6 {
				pinmux = <STM32_PINMUX('I', 6, AF13)>;
				slew-rate = "very-high-speed";
			};

			/omit-if-no-ref/ dcmi_d7_pi7: dcmi_d7_pi7 {
				pinmux = <STM32_PINMUX('I', 7, AF13)>;
				slew-rate = "very-high-speed";
			};

			/* ETH */

			/omit-if-no-ref/ eth_crs_pa0: eth_crs_pa0 {
				pinmux = <STM32_PINMUX('A', 0, AF11)>;
				slew-rate = "very-high-speed";
			};

			/omit-if-no-ref/ eth_ref_clk_pa1: eth_ref_clk_pa1 {
				pinmux = <STM32_PINMUX('A', 1, AF11)>;
				slew-rate = "very-high-speed";
			};

			/omit-if-no-ref/ eth_rx_clk_pa1: eth_rx_clk_pa1 {
				pinmux = <STM32_PINMUX('A', 1, AF11)>;
				slew-rate = "very-high-speed";
			};

			/omit-if-no-ref/ eth_mdio_pa2: eth_mdio_pa2 {
				pinmux = <STM32_PINMUX('A', 2, AF11)>;
				slew-rate = "very-high-speed";
			};

			/omit-if-no-ref/ eth_col_pa3: eth_col_pa3 {
				pinmux = <STM32_PINMUX('A', 3, AF11)>;
				slew-rate = "very-high-speed";
			};

			/omit-if-no-ref/ eth_tx_en_pa5: eth_tx_en_pa5 {
				pinmux = <STM32_PINMUX('A', 5, AF11)>;
				slew-rate = "very-high-speed";
			};

			/omit-if-no-ref/ eth_crs_dv_pa7: eth_crs_dv_pa7 {
				pinmux = <STM32_PINMUX('A', 7, AF11)>;
				slew-rate = "very-high-speed";
			};

			/omit-if-no-ref/ eth_rx_dv_pa7: eth_rx_dv_pa7 {
				pinmux = <STM32_PINMUX('A', 7, AF11)>;
				slew-rate = "very-high-speed";
			};

			/omit-if-no-ref/ eth_rxd2_pb0: eth_rxd2_pb0 {
				pinmux = <STM32_PINMUX('B', 0, AF11)>;
				slew-rate = "very-high-speed";
			};

			/omit-if-no-ref/ eth_rxd3_pb1: eth_rxd3_pb1 {
				pinmux = <STM32_PINMUX('B', 1, AF11)>;
				slew-rate = "very-high-speed";
			};

			/omit-if-no-ref/ eth_pps_out_pb5: eth_pps_out_pb5 {
				pinmux = <STM32_PINMUX('B', 5, AF11)>;
				slew-rate = "very-high-speed";
			};

			/omit-if-no-ref/ eth_txd3_pb8: eth_txd3_pb8 {
				pinmux = <STM32_PINMUX('B', 8, AF11)>;
				slew-rate = "very-high-speed";
			};

			/omit-if-no-ref/ eth_rx_er_pb10: eth_rx_er_pb10 {
				pinmux = <STM32_PINMUX('B', 10, AF11)>;
				slew-rate = "very-high-speed";
			};

			/omit-if-no-ref/ eth_tx_en_pb11: eth_tx_en_pb11 {
				pinmux = <STM32_PINMUX('B', 11, AF11)>;
				slew-rate = "very-high-speed";
			};

			/omit-if-no-ref/ eth_txd0_pb12: eth_txd0_pb12 {
				pinmux = <STM32_PINMUX('B', 12, AF11)>;
				slew-rate = "very-high-speed";
			};

			/omit-if-no-ref/ eth_txd1_pb15: eth_txd1_pb15 {
				pinmux = <STM32_PINMUX('B', 15, AF11)>;
				slew-rate = "very-high-speed";
			};

			/omit-if-no-ref/ eth_mdc_pc1: eth_mdc_pc1 {
				pinmux = <STM32_PINMUX('C', 1, AF11)>;
				slew-rate = "very-high-speed";
			};

			/omit-if-no-ref/ eth_txd2_pc2: eth_txd2_pc2 {
				pinmux = <STM32_PINMUX('C', 2, AF11)>;
				slew-rate = "very-high-speed";
			};

			/omit-if-no-ref/ eth_tx_clk_pc3: eth_tx_clk_pc3 {
				pinmux = <STM32_PINMUX('C', 3, AF11)>;
				slew-rate = "very-high-speed";
			};

			/omit-if-no-ref/ eth_rxd0_pc4: eth_rxd0_pc4 {
				pinmux = <STM32_PINMUX('C', 4, AF11)>;
				slew-rate = "very-high-speed";
			};

			/omit-if-no-ref/ eth_rxd1_pc5: eth_rxd1_pc5 {
				pinmux = <STM32_PINMUX('C', 5, AF11)>;
				slew-rate = "very-high-speed";
			};

			/omit-if-no-ref/ eth_txd0_pc10: eth_txd0_pc10 {
				pinmux = <STM32_PINMUX('C', 10, AF11)>;
				slew-rate = "very-high-speed";
			};

			/omit-if-no-ref/ eth_txd3_pe2: eth_txd3_pe2 {
				pinmux = <STM32_PINMUX('E', 2, AF11)>;
				slew-rate = "very-high-speed";
			};

			/omit-if-no-ref/ eth_pps_out_pg8: eth_pps_out_pg8 {
				pinmux = <STM32_PINMUX('G', 8, AF11)>;
				slew-rate = "very-high-speed";
			};

			/omit-if-no-ref/ eth_tx_en_pg11: eth_tx_en_pg11 {
				pinmux = <STM32_PINMUX('G', 11, AF11)>;
				slew-rate = "very-high-speed";
			};

			/omit-if-no-ref/ eth_txd1_pg12: eth_txd1_pg12 {
				pinmux = <STM32_PINMUX('G', 12, AF11)>;
				slew-rate = "very-high-speed";
			};

			/omit-if-no-ref/ eth_txd0_pg13: eth_txd0_pg13 {
				pinmux = <STM32_PINMUX('G', 13, AF11)>;
				slew-rate = "very-high-speed";
			};

			/omit-if-no-ref/ eth_txd1_pg14: eth_txd1_pg14 {
				pinmux = <STM32_PINMUX('G', 14, AF11)>;
				slew-rate = "very-high-speed";
			};

			/omit-if-no-ref/ eth_crs_ph2: eth_crs_ph2 {
				pinmux = <STM32_PINMUX('H', 2, AF11)>;
				slew-rate = "very-high-speed";
			};

			/omit-if-no-ref/ eth_col_ph3: eth_col_ph3 {
				pinmux = <STM32_PINMUX('H', 3, AF11)>;
				slew-rate = "very-high-speed";
			};

			/omit-if-no-ref/ eth_rxd2_ph6: eth_rxd2_ph6 {
				pinmux = <STM32_PINMUX('H', 6, AF11)>;
				slew-rate = "very-high-speed";
			};

			/omit-if-no-ref/ eth_rxd3_ph7: eth_rxd3_ph7 {
				pinmux = <STM32_PINMUX('H', 7, AF11)>;
				slew-rate = "very-high-speed";
			};

			/* FDCAN_RX */

			/omit-if-no-ref/ fdcan1_rx_pa11: fdcan1_rx_pa11 {
				pinmux = <STM32_PINMUX('A', 11, AF9)>;
			};

			/omit-if-no-ref/ fdcan1_rx_pb8: fdcan1_rx_pb8 {
				pinmux = <STM32_PINMUX('B', 8, AF9)>;
			};

			/omit-if-no-ref/ fdcan1_rx_pd0: fdcan1_rx_pd0 {
				pinmux = <STM32_PINMUX('D', 0, AF9)>;
			};

			/omit-if-no-ref/ fdcan1_rx_pe0: fdcan1_rx_pe0 {
				pinmux = <STM32_PINMUX('E', 0, AF9)>;
			};

			/omit-if-no-ref/ fdcan1_rx_ph14: fdcan1_rx_ph14 {
				pinmux = <STM32_PINMUX('H', 14, AF9)>;
			};

			/omit-if-no-ref/ fdcan2_rx_pb5: fdcan2_rx_pb5 {
				pinmux = <STM32_PINMUX('B', 5, AF9)>;
			};

			/omit-if-no-ref/ fdcan2_rx_pb12: fdcan2_rx_pb12 {
				pinmux = <STM32_PINMUX('B', 12, AF9)>;
			};

			/omit-if-no-ref/ fdcan2_rx_pd9: fdcan2_rx_pd9 {
				pinmux = <STM32_PINMUX('D', 9, AF9)>;
			};

			/* FDCAN_TX */

			/omit-if-no-ref/ fdcan1_tx_pa12: fdcan1_tx_pa12 {
				pinmux = <STM32_PINMUX('A', 12, AF9)>;
			};

			/omit-if-no-ref/ fdcan1_tx_pb7: fdcan1_tx_pb7 {
				pinmux = <STM32_PINMUX('B', 7, AF9)>;
			};

			/omit-if-no-ref/ fdcan1_tx_pb9: fdcan1_tx_pb9 {
				pinmux = <STM32_PINMUX('B', 9, AF9)>;
			};

			/omit-if-no-ref/ fdcan1_tx_pd1: fdcan1_tx_pd1 {
				pinmux = <STM32_PINMUX('D', 1, AF9)>;
			};

			/omit-if-no-ref/ fdcan1_tx_pd5: fdcan1_tx_pd5 {
				pinmux = <STM32_PINMUX('D', 5, AF9)>;
			};

			/omit-if-no-ref/ fdcan1_tx_pe1: fdcan1_tx_pe1 {
				pinmux = <STM32_PINMUX('E', 1, AF9)>;
			};

			/omit-if-no-ref/ fdcan1_tx_ph13: fdcan1_tx_ph13 {
				pinmux = <STM32_PINMUX('H', 13, AF9)>;
			};

			/omit-if-no-ref/ fdcan2_tx_pa10: fdcan2_tx_pa10 {
				pinmux = <STM32_PINMUX('A', 10, AF9)>;
			};

			/omit-if-no-ref/ fdcan2_tx_pb6: fdcan2_tx_pb6 {
				pinmux = <STM32_PINMUX('B', 6, AF9)>;
			};

			/omit-if-no-ref/ fdcan2_tx_pb13: fdcan2_tx_pb13 {
				pinmux = <STM32_PINMUX('B', 13, AF9)>;
			};

			/* FMC */

			/omit-if-no-ref/ fmc_nwe_pa7: fmc_nwe_pa7 {
				pinmux = <STM32_PINMUX('A', 7, AF13)>;
				bias-pull-up;
				slew-rate = "very-high-speed";
			};

			/omit-if-no-ref/ fmc_sdnwe_pa7: fmc_sdnwe_pa7 {
				pinmux = <STM32_PINMUX('A', 7, AF12)>;
				bias-pull-up;
				slew-rate = "very-high-speed";
			};

			/omit-if-no-ref/ fmc_noe_pa8: fmc_noe_pa8 {
				pinmux = <STM32_PINMUX('A', 8, AF12)>;
				bias-pull-up;
				slew-rate = "very-high-speed";
			};

			/omit-if-no-ref/ fmc_nwe_pa9: fmc_nwe_pa9 {
				pinmux = <STM32_PINMUX('A', 9, AF12)>;
				bias-pull-up;
				slew-rate = "very-high-speed";
			};

			/omit-if-no-ref/ fmc_nbl1_pa15: fmc_nbl1_pa15 {
				pinmux = <STM32_PINMUX('A', 15, AF12)>;
				bias-pull-up;
				slew-rate = "very-high-speed";
			};

			/omit-if-no-ref/ fmc_sdcke1_pb5: fmc_sdcke1_pb5 {
				pinmux = <STM32_PINMUX('B', 5, AF12)>;
				bias-pull-up;
				slew-rate = "very-high-speed";
			};

			/omit-if-no-ref/ fmc_sdne1_pb6: fmc_sdne1_pb6 {
				pinmux = <STM32_PINMUX('B', 6, AF12)>;
				bias-pull-up;
				slew-rate = "very-high-speed";
			};

			/omit-if-no-ref/ fmc_nl_pb7: fmc_nl_pb7 {
				pinmux = <STM32_PINMUX('B', 7, AF12)>;
				bias-pull-up;
				slew-rate = "very-high-speed";
			};

			/omit-if-no-ref/ fmc_nbl1_pb11: fmc_nbl1_pb11 {
				pinmux = <STM32_PINMUX('B', 11, AF12)>;
				bias-pull-up;
				slew-rate = "very-high-speed";
			};

			/omit-if-no-ref/ fmc_a25_pc0: fmc_a25_pc0 {
				pinmux = <STM32_PINMUX('C', 0, AF9)>;
				bias-pull-up;
				slew-rate = "very-high-speed";
			};

			/omit-if-no-ref/ fmc_sdnwe_pc0: fmc_sdnwe_pc0 {
				pinmux = <STM32_PINMUX('C', 0, AF12)>;
				bias-pull-up;
				slew-rate = "very-high-speed";
			};

			/omit-if-no-ref/ fmc_sdne0_pc2: fmc_sdne0_pc2 {
				pinmux = <STM32_PINMUX('C', 2, AF12)>;
				bias-pull-up;
				slew-rate = "very-high-speed";
			};

			/omit-if-no-ref/ fmc_sdcke0_pc3: fmc_sdcke0_pc3 {
				pinmux = <STM32_PINMUX('C', 3, AF12)>;
				bias-pull-up;
				slew-rate = "very-high-speed";
			};

			/omit-if-no-ref/ fmc_sdne0_pc4: fmc_sdne0_pc4 {
				pinmux = <STM32_PINMUX('C', 4, AF12)>;
				bias-pull-up;
				slew-rate = "very-high-speed";
			};

			/omit-if-no-ref/ fmc_sdcke0_pc5: fmc_sdcke0_pc5 {
				pinmux = <STM32_PINMUX('C', 5, AF12)>;
				bias-pull-up;
				slew-rate = "very-high-speed";
			};

			/omit-if-no-ref/ fmc_nwait_pc6: fmc_nwait_pc6 {
				pinmux = <STM32_PINMUX('C', 6, AF9)>;
				bias-pull-up;
				slew-rate = "very-high-speed";
			};

			/omit-if-no-ref/ fmc_ne1_pc7: fmc_ne1_pc7 {
				pinmux = <STM32_PINMUX('C', 7, AF9)>;
				bias-pull-up;
				slew-rate = "very-high-speed";
			};

			/omit-if-no-ref/ fmc_int_pc8: fmc_int_pc8 {
				pinmux = <STM32_PINMUX('C', 8, AF10)>;
				bias-pull-up;
				slew-rate = "very-high-speed";
			};

			/omit-if-no-ref/ fmc_nce_pc8: fmc_nce_pc8 {
				pinmux = <STM32_PINMUX('C', 8, AF9)>;
				bias-pull-up;
				slew-rate = "very-high-speed";
			};

			/omit-if-no-ref/ fmc_ne2_pc8: fmc_ne2_pc8 {
				pinmux = <STM32_PINMUX('C', 8, AF9)>;
				bias-pull-up;
				slew-rate = "very-high-speed";
			};

			/omit-if-no-ref/ fmc_d2_pd0: fmc_d2_pd0 {
				pinmux = <STM32_PINMUX('D', 0, AF12)>;
				bias-pull-up;
				slew-rate = "very-high-speed";
			};

			/omit-if-no-ref/ fmc_d3_pd1: fmc_d3_pd1 {
				pinmux = <STM32_PINMUX('D', 1, AF12)>;
				bias-pull-up;
				slew-rate = "very-high-speed";
			};

			/omit-if-no-ref/ fmc_clk_pd3: fmc_clk_pd3 {
				pinmux = <STM32_PINMUX('D', 3, AF12)>;
				bias-pull-up;
				slew-rate = "very-high-speed";
			};

			/omit-if-no-ref/ fmc_noe_pd4: fmc_noe_pd4 {
				pinmux = <STM32_PINMUX('D', 4, AF12)>;
				bias-pull-up;
				slew-rate = "very-high-speed";
			};

			/omit-if-no-ref/ fmc_nwe_pd5: fmc_nwe_pd5 {
				pinmux = <STM32_PINMUX('D', 5, AF12)>;
				bias-pull-up;
				slew-rate = "very-high-speed";
			};

			/omit-if-no-ref/ fmc_nwait_pd6: fmc_nwait_pd6 {
				pinmux = <STM32_PINMUX('D', 6, AF12)>;
				bias-pull-up;
				slew-rate = "very-high-speed";
			};

			/omit-if-no-ref/ fmc_nce_pd7: fmc_nce_pd7 {
				pinmux = <STM32_PINMUX('D', 7, AF12)>;
				bias-pull-up;
				slew-rate = "very-high-speed";
			};

			/omit-if-no-ref/ fmc_ne1_pd7: fmc_ne1_pd7 {
				pinmux = <STM32_PINMUX('D', 7, AF12)>;
				bias-pull-up;
				slew-rate = "very-high-speed";
			};

			/omit-if-no-ref/ fmc_d13_pd8: fmc_d13_pd8 {
				pinmux = <STM32_PINMUX('D', 8, AF12)>;
				bias-pull-up;
				slew-rate = "very-high-speed";
			};

			/omit-if-no-ref/ fmc_d14_pd9: fmc_d14_pd9 {
				pinmux = <STM32_PINMUX('D', 9, AF12)>;
				bias-pull-up;
				slew-rate = "very-high-speed";
			};

			/omit-if-no-ref/ fmc_d15_pd10: fmc_d15_pd10 {
				pinmux = <STM32_PINMUX('D', 10, AF12)>;
				bias-pull-up;
				slew-rate = "very-high-speed";
			};

			/omit-if-no-ref/ fmc_a16_pd11: fmc_a16_pd11 {
				pinmux = <STM32_PINMUX('D', 11, AF12)>;
				bias-pull-up;
				slew-rate = "very-high-speed";
			};

			/omit-if-no-ref/ fmc_a17_pd12: fmc_a17_pd12 {
				pinmux = <STM32_PINMUX('D', 12, AF12)>;
				bias-pull-up;
				slew-rate = "very-high-speed";
			};

			/omit-if-no-ref/ fmc_a18_pd13: fmc_a18_pd13 {
				pinmux = <STM32_PINMUX('D', 13, AF12)>;
				bias-pull-up;
				slew-rate = "very-high-speed";
			};

			/omit-if-no-ref/ fmc_d0_pd14: fmc_d0_pd14 {
				pinmux = <STM32_PINMUX('D', 14, AF12)>;
				bias-pull-up;
				slew-rate = "very-high-speed";
			};

			/omit-if-no-ref/ fmc_d1_pd15: fmc_d1_pd15 {
				pinmux = <STM32_PINMUX('D', 15, AF12)>;
				bias-pull-up;
				slew-rate = "very-high-speed";
			};

			/omit-if-no-ref/ fmc_nbl0_pe0: fmc_nbl0_pe0 {
				pinmux = <STM32_PINMUX('E', 0, AF12)>;
				bias-pull-up;
				slew-rate = "very-high-speed";
			};

			/omit-if-no-ref/ fmc_nbl1_pe1: fmc_nbl1_pe1 {
				pinmux = <STM32_PINMUX('E', 1, AF12)>;
				bias-pull-up;
				slew-rate = "very-high-speed";
			};

			/omit-if-no-ref/ fmc_a23_pe2: fmc_a23_pe2 {
				pinmux = <STM32_PINMUX('E', 2, AF12)>;
				bias-pull-up;
				slew-rate = "very-high-speed";
			};

			/omit-if-no-ref/ fmc_a19_pe3: fmc_a19_pe3 {
				pinmux = <STM32_PINMUX('E', 3, AF12)>;
				bias-pull-up;
				slew-rate = "very-high-speed";
			};

			/omit-if-no-ref/ fmc_a20_pe4: fmc_a20_pe4 {
				pinmux = <STM32_PINMUX('E', 4, AF12)>;
				bias-pull-up;
				slew-rate = "very-high-speed";
			};

			/omit-if-no-ref/ fmc_a21_pe5: fmc_a21_pe5 {
				pinmux = <STM32_PINMUX('E', 5, AF12)>;
				bias-pull-up;
				slew-rate = "very-high-speed";
			};

			/omit-if-no-ref/ fmc_a22_pe6: fmc_a22_pe6 {
				pinmux = <STM32_PINMUX('E', 6, AF12)>;
				bias-pull-up;
				slew-rate = "very-high-speed";
			};

			/omit-if-no-ref/ fmc_d4_pe7: fmc_d4_pe7 {
				pinmux = <STM32_PINMUX('E', 7, AF12)>;
				bias-pull-up;
				slew-rate = "very-high-speed";
			};

			/omit-if-no-ref/ fmc_d5_pe8: fmc_d5_pe8 {
				pinmux = <STM32_PINMUX('E', 8, AF12)>;
				bias-pull-up;
				slew-rate = "very-high-speed";
			};

			/omit-if-no-ref/ fmc_d6_pe9: fmc_d6_pe9 {
				pinmux = <STM32_PINMUX('E', 9, AF12)>;
				bias-pull-up;
				slew-rate = "very-high-speed";
			};

			/omit-if-no-ref/ fmc_d7_pe10: fmc_d7_pe10 {
				pinmux = <STM32_PINMUX('E', 10, AF12)>;
				bias-pull-up;
				slew-rate = "very-high-speed";
			};

			/omit-if-no-ref/ fmc_d8_pe11: fmc_d8_pe11 {
				pinmux = <STM32_PINMUX('E', 11, AF12)>;
				bias-pull-up;
				slew-rate = "very-high-speed";
			};

			/omit-if-no-ref/ fmc_d9_pe12: fmc_d9_pe12 {
				pinmux = <STM32_PINMUX('E', 12, AF12)>;
				bias-pull-up;
				slew-rate = "very-high-speed";
			};

			/omit-if-no-ref/ fmc_d10_pe13: fmc_d10_pe13 {
				pinmux = <STM32_PINMUX('E', 13, AF12)>;
				bias-pull-up;
				slew-rate = "very-high-speed";
			};

			/omit-if-no-ref/ fmc_d11_pe14: fmc_d11_pe14 {
				pinmux = <STM32_PINMUX('E', 14, AF12)>;
				bias-pull-up;
				slew-rate = "very-high-speed";
			};

			/omit-if-no-ref/ fmc_d12_pe15: fmc_d12_pe15 {
				pinmux = <STM32_PINMUX('E', 15, AF12)>;
				bias-pull-up;
				slew-rate = "very-high-speed";
			};

			/omit-if-no-ref/ fmc_a0_pf0: fmc_a0_pf0 {
				pinmux = <STM32_PINMUX('F', 0, AF12)>;
				bias-pull-up;
				slew-rate = "very-high-speed";
			};

			/omit-if-no-ref/ fmc_a1_pf1: fmc_a1_pf1 {
				pinmux = <STM32_PINMUX('F', 1, AF12)>;
				bias-pull-up;
				slew-rate = "very-high-speed";
			};

			/omit-if-no-ref/ fmc_a2_pf2: fmc_a2_pf2 {
				pinmux = <STM32_PINMUX('F', 2, AF12)>;
				bias-pull-up;
				slew-rate = "very-high-speed";
			};

			/omit-if-no-ref/ fmc_a3_pf3: fmc_a3_pf3 {
				pinmux = <STM32_PINMUX('F', 3, AF12)>;
				bias-pull-up;
				slew-rate = "very-high-speed";
			};

			/omit-if-no-ref/ fmc_a4_pf4: fmc_a4_pf4 {
				pinmux = <STM32_PINMUX('F', 4, AF12)>;
				bias-pull-up;
				slew-rate = "very-high-speed";
			};

			/omit-if-no-ref/ fmc_a5_pf5: fmc_a5_pf5 {
				pinmux = <STM32_PINMUX('F', 5, AF12)>;
				bias-pull-up;
				slew-rate = "very-high-speed";
			};

			/omit-if-no-ref/ fmc_sdnras_pf11: fmc_sdnras_pf11 {
				pinmux = <STM32_PINMUX('F', 11, AF12)>;
				bias-pull-up;
				slew-rate = "very-high-speed";
			};

			/omit-if-no-ref/ fmc_a6_pf12: fmc_a6_pf12 {
				pinmux = <STM32_PINMUX('F', 12, AF12)>;
				bias-pull-up;
				slew-rate = "very-high-speed";
			};

			/omit-if-no-ref/ fmc_a7_pf13: fmc_a7_pf13 {
				pinmux = <STM32_PINMUX('F', 13, AF12)>;
				bias-pull-up;
				slew-rate = "very-high-speed";
			};

			/omit-if-no-ref/ fmc_a8_pf14: fmc_a8_pf14 {
				pinmux = <STM32_PINMUX('F', 14, AF12)>;
				bias-pull-up;
				slew-rate = "very-high-speed";
			};

			/omit-if-no-ref/ fmc_a9_pf15: fmc_a9_pf15 {
				pinmux = <STM32_PINMUX('F', 15, AF12)>;
				bias-pull-up;
				slew-rate = "very-high-speed";
			};

			/omit-if-no-ref/ fmc_a10_pg0: fmc_a10_pg0 {
				pinmux = <STM32_PINMUX('G', 0, AF12)>;
				bias-pull-up;
				slew-rate = "very-high-speed";
			};

			/omit-if-no-ref/ fmc_a11_pg1: fmc_a11_pg1 {
				pinmux = <STM32_PINMUX('G', 1, AF12)>;
				bias-pull-up;
				slew-rate = "very-high-speed";
			};

			/omit-if-no-ref/ fmc_a12_pg2: fmc_a12_pg2 {
				pinmux = <STM32_PINMUX('G', 2, AF12)>;
				bias-pull-up;
				slew-rate = "very-high-speed";
			};

			/omit-if-no-ref/ fmc_a13_pg3: fmc_a13_pg3 {
				pinmux = <STM32_PINMUX('G', 3, AF12)>;
				bias-pull-up;
				slew-rate = "very-high-speed";
			};

			/omit-if-no-ref/ fmc_a14_pg4: fmc_a14_pg4 {
				pinmux = <STM32_PINMUX('G', 4, AF12)>;
				bias-pull-up;
				slew-rate = "very-high-speed";
			};

			/omit-if-no-ref/ fmc_a15_pg5: fmc_a15_pg5 {
				pinmux = <STM32_PINMUX('G', 5, AF12)>;
				bias-pull-up;
				slew-rate = "very-high-speed";
			};

			/omit-if-no-ref/ fmc_ne3_pg6: fmc_ne3_pg6 {
				pinmux = <STM32_PINMUX('G', 6, AF12)>;
				bias-pull-up;
				slew-rate = "very-high-speed";
			};

			/omit-if-no-ref/ fmc_int_pg7: fmc_int_pg7 {
				pinmux = <STM32_PINMUX('G', 7, AF12)>;
				bias-pull-up;
				slew-rate = "very-high-speed";
			};

			/omit-if-no-ref/ fmc_sdclk_pg8: fmc_sdclk_pg8 {
				pinmux = <STM32_PINMUX('G', 8, AF12)>;
				bias-pull-up;
				slew-rate = "very-high-speed";
			};

			/omit-if-no-ref/ fmc_nce_pg9: fmc_nce_pg9 {
				pinmux = <STM32_PINMUX('G', 9, AF12)>;
				bias-pull-up;
				slew-rate = "very-high-speed";
			};

			/omit-if-no-ref/ fmc_ne2_pg9: fmc_ne2_pg9 {
				pinmux = <STM32_PINMUX('G', 9, AF12)>;
				bias-pull-up;
				slew-rate = "very-high-speed";
			};

			/omit-if-no-ref/ fmc_ne3_pg10: fmc_ne3_pg10 {
				pinmux = <STM32_PINMUX('G', 10, AF12)>;
				bias-pull-up;
				slew-rate = "very-high-speed";
			};

			/omit-if-no-ref/ fmc_ne4_pg12: fmc_ne4_pg12 {
				pinmux = <STM32_PINMUX('G', 12, AF12)>;
				bias-pull-up;
				slew-rate = "very-high-speed";
			};

			/omit-if-no-ref/ fmc_a24_pg13: fmc_a24_pg13 {
				pinmux = <STM32_PINMUX('G', 13, AF12)>;
				bias-pull-up;
				slew-rate = "very-high-speed";
			};

			/omit-if-no-ref/ fmc_a25_pg14: fmc_a25_pg14 {
				pinmux = <STM32_PINMUX('G', 14, AF12)>;
				bias-pull-up;
				slew-rate = "very-high-speed";
			};

			/omit-if-no-ref/ fmc_sdncas_pg15: fmc_sdncas_pg15 {
				pinmux = <STM32_PINMUX('G', 15, AF12)>;
				bias-pull-up;
				slew-rate = "very-high-speed";
			};

			/omit-if-no-ref/ fmc_sdcke0_ph2: fmc_sdcke0_ph2 {
				pinmux = <STM32_PINMUX('H', 2, AF12)>;
				bias-pull-up;
				slew-rate = "very-high-speed";
			};

			/omit-if-no-ref/ fmc_sdne0_ph3: fmc_sdne0_ph3 {
				pinmux = <STM32_PINMUX('H', 3, AF12)>;
				bias-pull-up;
				slew-rate = "very-high-speed";
			};

			/omit-if-no-ref/ fmc_sdnwe_ph5: fmc_sdnwe_ph5 {
				pinmux = <STM32_PINMUX('H', 5, AF12)>;
				bias-pull-up;
				slew-rate = "very-high-speed";
			};

			/omit-if-no-ref/ fmc_sdne1_ph6: fmc_sdne1_ph6 {
				pinmux = <STM32_PINMUX('H', 6, AF12)>;
				bias-pull-up;
				slew-rate = "very-high-speed";
			};

			/omit-if-no-ref/ fmc_sdcke1_ph7: fmc_sdcke1_ph7 {
				pinmux = <STM32_PINMUX('H', 7, AF12)>;
				bias-pull-up;
				slew-rate = "very-high-speed";
			};

			/* I2C_SCL */

			/omit-if-no-ref/ i2c1_scl_pb6: i2c1_scl_pb6 {
				pinmux = <STM32_PINMUX('B', 6, AF4)>;
				bias-pull-up;
				drive-open-drain;
			};

			/omit-if-no-ref/ i2c1_scl_pb8: i2c1_scl_pb8 {
				pinmux = <STM32_PINMUX('B', 8, AF4)>;
				bias-pull-up;
				drive-open-drain;
			};

			/omit-if-no-ref/ i2c2_scl_pb10: i2c2_scl_pb10 {
				pinmux = <STM32_PINMUX('B', 10, AF4)>;
				bias-pull-up;
				drive-open-drain;
			};

			/omit-if-no-ref/ i2c2_scl_pf1: i2c2_scl_pf1 {
				pinmux = <STM32_PINMUX('F', 1, AF4)>;
				bias-pull-up;
				drive-open-drain;
			};

			/omit-if-no-ref/ i2c2_scl_ph4: i2c2_scl_ph4 {
				pinmux = <STM32_PINMUX('H', 4, AF4)>;
				bias-pull-up;
				drive-open-drain;
			};

			/omit-if-no-ref/ i2c3_scl_pa8: i2c3_scl_pa8 {
				pinmux = <STM32_PINMUX('A', 8, AF4)>;
				bias-pull-up;
				drive-open-drain;
			};

			/omit-if-no-ref/ i2c3_scl_ph7: i2c3_scl_ph7 {
				pinmux = <STM32_PINMUX('H', 7, AF4)>;
				bias-pull-up;
				drive-open-drain;
			};

			/omit-if-no-ref/ i2c4_scl_pb6: i2c4_scl_pb6 {
				pinmux = <STM32_PINMUX('B', 6, AF6)>;
				bias-pull-up;
				drive-open-drain;
			};

			/omit-if-no-ref/ i2c4_scl_pb8: i2c4_scl_pb8 {
				pinmux = <STM32_PINMUX('B', 8, AF6)>;
				bias-pull-up;
				drive-open-drain;
			};

			/omit-if-no-ref/ i2c4_scl_pd12: i2c4_scl_pd12 {
				pinmux = <STM32_PINMUX('D', 12, AF4)>;
				bias-pull-up;
				drive-open-drain;
			};

			/omit-if-no-ref/ i2c4_scl_pf5: i2c4_scl_pf5 {
				pinmux = <STM32_PINMUX('F', 5, AF4)>;
				bias-pull-up;
				drive-open-drain;
			};

			/omit-if-no-ref/ i2c4_scl_pg7: i2c4_scl_pg7 {
				pinmux = <STM32_PINMUX('G', 7, AF4)>;
				bias-pull-up;
				drive-open-drain;
			};

			/omit-if-no-ref/ i2c4_scl_ph11: i2c4_scl_ph11 {
				pinmux = <STM32_PINMUX('H', 11, AF4)>;
				bias-pull-up;
				drive-open-drain;
			};

			/* I2C_SDA */

			/omit-if-no-ref/ i2c1_sda_pb7: i2c1_sda_pb7 {
				pinmux = <STM32_PINMUX('B', 7, AF4)>;
				bias-pull-up;
				drive-open-drain;
			};

			/omit-if-no-ref/ i2c1_sda_pb9: i2c1_sda_pb9 {
				pinmux = <STM32_PINMUX('B', 9, AF4)>;
				bias-pull-up;
				drive-open-drain;
			};

			/omit-if-no-ref/ i2c2_sda_pb3: i2c2_sda_pb3 {
				pinmux = <STM32_PINMUX('B', 3, AF4)>;
				bias-pull-up;
				drive-open-drain;
			};

			/omit-if-no-ref/ i2c2_sda_pb11: i2c2_sda_pb11 {
				pinmux = <STM32_PINMUX('B', 11, AF4)>;
				bias-pull-up;
				drive-open-drain;
			};

			/omit-if-no-ref/ i2c2_sda_pb12: i2c2_sda_pb12 {
				pinmux = <STM32_PINMUX('B', 12, AF4)>;
				bias-pull-up;
				drive-open-drain;
			};

			/omit-if-no-ref/ i2c2_sda_pf0: i2c2_sda_pf0 {
				pinmux = <STM32_PINMUX('F', 0, AF4)>;
				bias-pull-up;
				drive-open-drain;
			};

			/omit-if-no-ref/ i2c2_sda_ph5: i2c2_sda_ph5 {
				pinmux = <STM32_PINMUX('H', 5, AF4)>;
				bias-pull-up;
				drive-open-drain;
			};

			/omit-if-no-ref/ i2c3_sda_pc9: i2c3_sda_pc9 {
				pinmux = <STM32_PINMUX('C', 9, AF4)>;
				bias-pull-up;
				drive-open-drain;
			};

			/omit-if-no-ref/ i2c3_sda_ph8: i2c3_sda_ph8 {
				pinmux = <STM32_PINMUX('H', 8, AF4)>;
				bias-pull-up;
				drive-open-drain;
			};

			/omit-if-no-ref/ i2c4_sda_pb7: i2c4_sda_pb7 {
				pinmux = <STM32_PINMUX('B', 7, AF6)>;
				bias-pull-up;
				drive-open-drain;
			};

			/omit-if-no-ref/ i2c4_sda_pb9: i2c4_sda_pb9 {
				pinmux = <STM32_PINMUX('B', 9, AF6)>;
				bias-pull-up;
				drive-open-drain;
			};

			/omit-if-no-ref/ i2c4_sda_pd13: i2c4_sda_pd13 {
				pinmux = <STM32_PINMUX('D', 13, AF4)>;
				bias-pull-up;
				drive-open-drain;
			};

			/omit-if-no-ref/ i2c4_sda_pf15: i2c4_sda_pf15 {
				pinmux = <STM32_PINMUX('F', 15, AF4)>;
				bias-pull-up;
				drive-open-drain;
			};

			/omit-if-no-ref/ i2c4_sda_pg6: i2c4_sda_pg6 {
				pinmux = <STM32_PINMUX('G', 6, AF4)>;
				bias-pull-up;
				drive-open-drain;
			};

			/omit-if-no-ref/ i2c4_sda_ph12: i2c4_sda_ph12 {
				pinmux = <STM32_PINMUX('H', 12, AF4)>;
				bias-pull-up;
				drive-open-drain;
			};

			/* I2C_SMBA */

			/omit-if-no-ref/ i2c1_smba_pb5: i2c1_smba_pb5 {
				pinmux = <STM32_PINMUX('B', 5, AF4)>;
				bias-pull-up;
			};

			/omit-if-no-ref/ i2c2_smba_pb13: i2c2_smba_pb13 {
				pinmux = <STM32_PINMUX('B', 13, AF4)>;
				bias-pull-up;
			};

			/omit-if-no-ref/ i2c2_smba_pf2: i2c2_smba_pf2 {
				pinmux = <STM32_PINMUX('F', 2, AF4)>;
				bias-pull-up;
			};

			/omit-if-no-ref/ i2c2_smba_ph6: i2c2_smba_ph6 {
				pinmux = <STM32_PINMUX('H', 6, AF4)>;
				bias-pull-up;
			};

			/omit-if-no-ref/ i2c3_smba_pa9: i2c3_smba_pa9 {
				pinmux = <STM32_PINMUX('A', 9, AF4)>;
				bias-pull-up;
			};

			/omit-if-no-ref/ i2c4_smba_pb5: i2c4_smba_pb5 {
				pinmux = <STM32_PINMUX('B', 5, AF6)>;
				bias-pull-up;
			};

			/omit-if-no-ref/ i2c4_smba_pd11: i2c4_smba_pd11 {
				pinmux = <STM32_PINMUX('D', 11, AF4)>;
				bias-pull-up;
			};

			/omit-if-no-ref/ i2c4_smba_pf13: i2c4_smba_pf13 {
				pinmux = <STM32_PINMUX('F', 13, AF4)>;
				bias-pull-up;
			};

			/omit-if-no-ref/ i2c4_smba_ph10: i2c4_smba_ph10 {
				pinmux = <STM32_PINMUX('H', 10, AF4)>;
				bias-pull-up;
			};

			/* I2S_CK */

			/omit-if-no-ref/ i2s1_ck_pa5: i2s1_ck_pa5 {
				pinmux = <STM32_PINMUX('A', 5, AF5)>;
				slew-rate = "very-high-speed";
			};

			/omit-if-no-ref/ i2s1_ck_pb3: i2s1_ck_pb3 {
				pinmux = <STM32_PINMUX('B', 3, AF5)>;
				slew-rate = "very-high-speed";
			};

			/omit-if-no-ref/ i2s1_ck_pg11: i2s1_ck_pg11 {
				pinmux = <STM32_PINMUX('G', 11, AF5)>;
				slew-rate = "very-high-speed";
			};

			/omit-if-no-ref/ i2s2_ck_pa9: i2s2_ck_pa9 {
				pinmux = <STM32_PINMUX('A', 9, AF5)>;
				slew-rate = "very-high-speed";
			};

			/omit-if-no-ref/ i2s2_ck_pa12: i2s2_ck_pa12 {
				pinmux = <STM32_PINMUX('A', 12, AF5)>;
				slew-rate = "very-high-speed";
			};

			/omit-if-no-ref/ i2s2_ck_pb10: i2s2_ck_pb10 {
				pinmux = <STM32_PINMUX('B', 10, AF5)>;
				slew-rate = "very-high-speed";
			};

			/omit-if-no-ref/ i2s2_ck_pb13: i2s2_ck_pb13 {
				pinmux = <STM32_PINMUX('B', 13, AF5)>;
				slew-rate = "very-high-speed";
			};

			/omit-if-no-ref/ i2s2_ck_pd3: i2s2_ck_pd3 {
				pinmux = <STM32_PINMUX('D', 3, AF5)>;
				slew-rate = "very-high-speed";
			};

			/omit-if-no-ref/ i2s2_ck_pi1: i2s2_ck_pi1 {
				pinmux = <STM32_PINMUX('I', 1, AF5)>;
				slew-rate = "very-high-speed";
			};

			/omit-if-no-ref/ i2s3_ck_pb3: i2s3_ck_pb3 {
				pinmux = <STM32_PINMUX('B', 3, AF6)>;
				slew-rate = "very-high-speed";
			};

			/omit-if-no-ref/ i2s3_ck_pc10: i2s3_ck_pc10 {
				pinmux = <STM32_PINMUX('C', 10, AF6)>;
				slew-rate = "very-high-speed";
			};

			/* I2S_MCK */

			/omit-if-no-ref/ i2s1_mck_pc4: i2s1_mck_pc4 {
				pinmux = <STM32_PINMUX('C', 4, AF5)>;
				slew-rate = "very-high-speed";
			};

			/omit-if-no-ref/ i2s2_mck_pc6: i2s2_mck_pc6 {
				pinmux = <STM32_PINMUX('C', 6, AF5)>;
				slew-rate = "very-high-speed";
			};

			/omit-if-no-ref/ i2s3_mck_pc7: i2s3_mck_pc7 {
				pinmux = <STM32_PINMUX('C', 7, AF6)>;
				slew-rate = "very-high-speed";
			};

			/* I2S_WS */

			/omit-if-no-ref/ i2s1_ws_pa4: i2s1_ws_pa4 {
				pinmux = <STM32_PINMUX('A', 4, AF5)>;
			};

			/omit-if-no-ref/ i2s1_ws_pa15: i2s1_ws_pa15 {
				pinmux = <STM32_PINMUX('A', 15, AF5)>;
			};

			/omit-if-no-ref/ i2s1_ws_pg10: i2s1_ws_pg10 {
				pinmux = <STM32_PINMUX('G', 10, AF5)>;
			};

			/omit-if-no-ref/ i2s2_ws_pa3: i2s2_ws_pa3 {
				pinmux = <STM32_PINMUX('A', 3, AF5)>;
			};

			/omit-if-no-ref/ i2s2_ws_pa11: i2s2_ws_pa11 {
				pinmux = <STM32_PINMUX('A', 11, AF5)>;
			};

			/omit-if-no-ref/ i2s2_ws_pb4: i2s2_ws_pb4 {
				pinmux = <STM32_PINMUX('B', 4, AF7)>;
			};

			/omit-if-no-ref/ i2s2_ws_pb9: i2s2_ws_pb9 {
				pinmux = <STM32_PINMUX('B', 9, AF5)>;
			};

			/omit-if-no-ref/ i2s2_ws_pb12: i2s2_ws_pb12 {
				pinmux = <STM32_PINMUX('B', 12, AF5)>;
			};

			/omit-if-no-ref/ i2s2_ws_pi0: i2s2_ws_pi0 {
				pinmux = <STM32_PINMUX('I', 0, AF5)>;
			};

			/omit-if-no-ref/ i2s3_ws_pa4: i2s3_ws_pa4 {
				pinmux = <STM32_PINMUX('A', 4, AF6)>;
			};

			/omit-if-no-ref/ i2s3_ws_pa15: i2s3_ws_pa15 {
				pinmux = <STM32_PINMUX('A', 15, AF6)>;
			};

			/* I3C_SCL */

			/omit-if-no-ref/ i3c1_scl_pb6: i3c1_scl_pb6 {
				pinmux = <STM32_PINMUX('B', 6, AF3)>;
				slew-rate = "very-high-speed";
			};

			/omit-if-no-ref/ i3c1_scl_pb8: i3c1_scl_pb8 {
				pinmux = <STM32_PINMUX('B', 8, AF3)>;
				slew-rate = "very-high-speed";
			};

			/omit-if-no-ref/ i3c1_scl_pd12: i3c1_scl_pd12 {
				pinmux = <STM32_PINMUX('D', 12, AF5)>;
				slew-rate = "very-high-speed";
			};

			/omit-if-no-ref/ i3c1_scl_pf5: i3c1_scl_pf5 {
				pinmux = <STM32_PINMUX('F', 5, AF5)>;
				slew-rate = "very-high-speed";
			};

			/omit-if-no-ref/ i3c1_scl_pg7: i3c1_scl_pg7 {
				pinmux = <STM32_PINMUX('G', 7, AF3)>;
				slew-rate = "very-high-speed";
			};

			/omit-if-no-ref/ i3c1_scl_ph11: i3c1_scl_ph11 {
				pinmux = <STM32_PINMUX('H', 11, AF5)>;
				slew-rate = "very-high-speed";
			};

			/* I3C_SDA */

			/omit-if-no-ref/ i3c1_sda_pb7: i3c1_sda_pb7 {
				pinmux = <STM32_PINMUX('B', 7, AF3)>;
				slew-rate = "very-high-speed";
			};

			/omit-if-no-ref/ i3c1_sda_pb9: i3c1_sda_pb9 {
				pinmux = <STM32_PINMUX('B', 9, AF3)>;
				slew-rate = "very-high-speed";
			};

			/omit-if-no-ref/ i3c1_sda_pd13: i3c1_sda_pd13 {
				pinmux = <STM32_PINMUX('D', 13, AF5)>;
				slew-rate = "very-high-speed";
			};

			/omit-if-no-ref/ i3c1_sda_pf15: i3c1_sda_pf15 {
				pinmux = <STM32_PINMUX('F', 15, AF5)>;
				slew-rate = "very-high-speed";
			};

			/omit-if-no-ref/ i3c1_sda_pg6: i3c1_sda_pg6 {
				pinmux = <STM32_PINMUX('G', 6, AF3)>;
				slew-rate = "very-high-speed";
			};

			/omit-if-no-ref/ i3c1_sda_ph12: i3c1_sda_ph12 {
				pinmux = <STM32_PINMUX('H', 12, AF5)>;
				slew-rate = "very-high-speed";
			};

			/* JTAG PORT */

			/omit-if-no-ref/ debug_jtms_swdio_pa13: debug_jtms_swdio_pa13 {
				pinmux = <STM32_PINMUX('A', 13, AF0)>;
			};

			/omit-if-no-ref/ debug_jtck_swclk_pa14: debug_jtck_swclk_pa14 {
				pinmux = <STM32_PINMUX('A', 14, AF0)>;
			};

			/omit-if-no-ref/ debug_jtdi_pa15: debug_jtdi_pa15 {
				pinmux = <STM32_PINMUX('A', 15, AF0)>;
			};

			/omit-if-no-ref/ debug_jtdo_swo_pb3: debug_jtdo_swo_pb3 {
				pinmux = <STM32_PINMUX('B', 3, AF0)>;
			};

			/omit-if-no-ref/ debug_jtrst_pb4: debug_jtrst_pb4 {
				pinmux = <STM32_PINMUX('B', 4, AF0)>;
			};

			/* OCTOSPI */

			/omit-if-no-ref/ octospi1_dqs_pa1: octospi1_dqs_pa1 {
				pinmux = <STM32_PINMUX('A', 1, AF6)>;
				slew-rate = "very-high-speed";
			};

			/omit-if-no-ref/ octospi1_io3_pa1: octospi1_io3_pa1 {
				pinmux = <STM32_PINMUX('A', 1, AF9)>;
				slew-rate = "very-high-speed";
			};

			/omit-if-no-ref/ octospi1_clk_pa3: octospi1_clk_pa3 {
				pinmux = <STM32_PINMUX('A', 3, AF3)>;
				slew-rate = "very-high-speed";
			};

			/omit-if-no-ref/ octospi1_io3_pa6: octospi1_io3_pa6 {
				pinmux = <STM32_PINMUX('A', 6, AF6)>;
				slew-rate = "very-high-speed";
			};

			/omit-if-no-ref/ octospi1_io2_pa7: octospi1_io2_pa7 {
				pinmux = <STM32_PINMUX('A', 7, AF10)>;
				slew-rate = "very-high-speed";
			};

			/omit-if-no-ref/ octospi1_io1_pb0: octospi1_io1_pb0 {
				pinmux = <STM32_PINMUX('B', 0, AF6)>;
				slew-rate = "very-high-speed";
			};

			/omit-if-no-ref/ octospi1_io0_pb1: octospi1_io0_pb1 {
				pinmux = <STM32_PINMUX('B', 1, AF6)>;
				slew-rate = "very-high-speed";
			};

			/omit-if-no-ref/ octospi1_clk_pb2: octospi1_clk_pb2 {
				pinmux = <STM32_PINMUX('B', 2, AF9)>;
				slew-rate = "very-high-speed";
			};

			/omit-if-no-ref/ octospi1_dqs_pb2: octospi1_dqs_pb2 {
				pinmux = <STM32_PINMUX('B', 2, AF10)>;
				slew-rate = "very-high-speed";
			};

			/omit-if-no-ref/ octospi1_clk_pb4: octospi1_clk_pb4 {
				pinmux = <STM32_PINMUX('B', 4, AF3)>;
				slew-rate = "very-high-speed";
			};

			/omit-if-no-ref/ octospi1_nclk_pb5: octospi1_nclk_pb5 {
				pinmux = <STM32_PINMUX('B', 5, AF3)>;
				slew-rate = "very-high-speed";
			};

			/omit-if-no-ref/ octospi1_ncs_pb6: octospi1_ncs_pb6 {
				pinmux = <STM32_PINMUX('B', 6, AF10)>;
				slew-rate = "very-high-speed";
			};

			/omit-if-no-ref/ octospi1_ncs_pb10: octospi1_ncs_pb10 {
				pinmux = <STM32_PINMUX('B', 10, AF9)>;
				slew-rate = "very-high-speed";
			};

			/omit-if-no-ref/ octospi1_nclk_pb12: octospi1_nclk_pb12 {
				pinmux = <STM32_PINMUX('B', 12, AF3)>;
				slew-rate = "very-high-speed";
			};

			/omit-if-no-ref/ octospi1_clk_pb15: octospi1_clk_pb15 {
				pinmux = <STM32_PINMUX('B', 15, AF10)>;
				slew-rate = "very-high-speed";
			};

			/omit-if-no-ref/ octospi1_io7_pc0: octospi1_io7_pc0 {
				pinmux = <STM32_PINMUX('C', 0, AF10)>;
				slew-rate = "very-high-speed";
			};

			/omit-if-no-ref/ octospi1_io4_pc1: octospi1_io4_pc1 {
				pinmux = <STM32_PINMUX('C', 1, AF10)>;
				slew-rate = "very-high-speed";
			};

			/omit-if-no-ref/ octospi1_io2_pc2: octospi1_io2_pc2 {
				pinmux = <STM32_PINMUX('C', 2, AF9)>;
				slew-rate = "very-high-speed";
			};

			/omit-if-no-ref/ octospi1_io5_pc2: octospi1_io5_pc2 {
				pinmux = <STM32_PINMUX('C', 2, AF6)>;
				slew-rate = "very-high-speed";
			};

			/omit-if-no-ref/ octospi1_io0_pc3: octospi1_io0_pc3 {
				pinmux = <STM32_PINMUX('C', 3, AF9)>;
				slew-rate = "very-high-speed";
			};

			/omit-if-no-ref/ octospi1_io6_pc3: octospi1_io6_pc3 {
				pinmux = <STM32_PINMUX('C', 3, AF6)>;
				slew-rate = "very-high-speed";
			};

			/omit-if-no-ref/ octospi1_dqs_pc5: octospi1_dqs_pc5 {
				pinmux = <STM32_PINMUX('C', 5, AF10)>;
				slew-rate = "very-high-speed";
			};

			/omit-if-no-ref/ octospi1_io5_pc6: octospi1_io5_pc6 {
				pinmux = <STM32_PINMUX('C', 6, AF11)>;
				slew-rate = "very-high-speed";
			};

			/omit-if-no-ref/ octospi1_io6_pc7: octospi1_io6_pc7 {
				pinmux = <STM32_PINMUX('C', 7, AF11)>;
				slew-rate = "very-high-speed";
			};

			/omit-if-no-ref/ octospi1_io0_pc9: octospi1_io0_pc9 {
				pinmux = <STM32_PINMUX('C', 9, AF9)>;
				slew-rate = "very-high-speed";
			};

			/omit-if-no-ref/ octospi1_io1_pc10: octospi1_io1_pc10 {
				pinmux = <STM32_PINMUX('C', 10, AF9)>;
				slew-rate = "very-high-speed";
			};

			/omit-if-no-ref/ octospi1_ncs_pc11: octospi1_ncs_pc11 {
				pinmux = <STM32_PINMUX('C', 11, AF9)>;
				slew-rate = "very-high-speed";
			};

			/omit-if-no-ref/ octospi1_io4_pd4: octospi1_io4_pd4 {
				pinmux = <STM32_PINMUX('D', 4, AF10)>;
				slew-rate = "very-high-speed";
			};

			/omit-if-no-ref/ octospi1_io5_pd5: octospi1_io5_pd5 {
				pinmux = <STM32_PINMUX('D', 5, AF10)>;
				slew-rate = "very-high-speed";
			};

			/omit-if-no-ref/ octospi1_io6_pd6: octospi1_io6_pd6 {
				pinmux = <STM32_PINMUX('D', 6, AF10)>;
				slew-rate = "very-high-speed";
			};

			/omit-if-no-ref/ octospi1_io7_pd7: octospi1_io7_pd7 {
				pinmux = <STM32_PINMUX('D', 7, AF10)>;
				slew-rate = "very-high-speed";
			};

			/omit-if-no-ref/ octospi1_io0_pd11: octospi1_io0_pd11 {
				pinmux = <STM32_PINMUX('D', 11, AF9)>;
				slew-rate = "very-high-speed";
			};

			/omit-if-no-ref/ octospi1_io1_pd12: octospi1_io1_pd12 {
				pinmux = <STM32_PINMUX('D', 12, AF9)>;
				slew-rate = "very-high-speed";
			};

			/omit-if-no-ref/ octospi1_io3_pd13: octospi1_io3_pd13 {
				pinmux = <STM32_PINMUX('D', 13, AF9)>;
				slew-rate = "very-high-speed";
			};

			/omit-if-no-ref/ octospi1_io2_pe2: octospi1_io2_pe2 {
				pinmux = <STM32_PINMUX('E', 2, AF9)>;
				slew-rate = "very-high-speed";
			};

			/omit-if-no-ref/ octospi1_io4_pe7: octospi1_io4_pe7 {
				pinmux = <STM32_PINMUX('E', 7, AF10)>;
				slew-rate = "very-high-speed";
			};

			/omit-if-no-ref/ octospi1_io5_pe8: octospi1_io5_pe8 {
				pinmux = <STM32_PINMUX('E', 8, AF10)>;
				slew-rate = "very-high-speed";
			};

			/omit-if-no-ref/ octospi1_io6_pe9: octospi1_io6_pe9 {
				pinmux = <STM32_PINMUX('E', 9, AF10)>;
				slew-rate = "very-high-speed";
			};

			/omit-if-no-ref/ octospi1_io7_pe10: octospi1_io7_pe10 {
				pinmux = <STM32_PINMUX('E', 10, AF10)>;
				slew-rate = "very-high-speed";
			};

			/omit-if-no-ref/ octospi1_ncs_pe11: octospi1_ncs_pe11 {
				pinmux = <STM32_PINMUX('E', 11, AF6)>;
				slew-rate = "very-high-speed";
			};

			/omit-if-no-ref/ octospi1_io3_pf6: octospi1_io3_pf6 {
				pinmux = <STM32_PINMUX('F', 6, AF10)>;
				slew-rate = "very-high-speed";
			};

			/omit-if-no-ref/ octospi1_io2_pf7: octospi1_io2_pf7 {
				pinmux = <STM32_PINMUX('F', 7, AF10)>;
				slew-rate = "very-high-speed";
			};

			/omit-if-no-ref/ octospi1_io0_pf8: octospi1_io0_pf8 {
				pinmux = <STM32_PINMUX('F', 8, AF10)>;
				slew-rate = "very-high-speed";
			};

			/omit-if-no-ref/ octospi1_io1_pf9: octospi1_io1_pf9 {
				pinmux = <STM32_PINMUX('F', 9, AF10)>;
				slew-rate = "very-high-speed";
			};

			/omit-if-no-ref/ octospi1_clk_pf10: octospi1_clk_pf10 {
				pinmux = <STM32_PINMUX('F', 10, AF9)>;
				slew-rate = "very-high-speed";
			};

			/omit-if-no-ref/ octospi1_nclk_pf11: octospi1_nclk_pf11 {
				pinmux = <STM32_PINMUX('F', 11, AF9)>;
				slew-rate = "very-high-speed";
			};

			/omit-if-no-ref/ octospi1_ncs_pg6: octospi1_ncs_pg6 {
				pinmux = <STM32_PINMUX('G', 6, AF10)>;
				slew-rate = "very-high-speed";
			};

			/omit-if-no-ref/ octospi1_io6_pg9: octospi1_io6_pg9 {
				pinmux = <STM32_PINMUX('G', 9, AF9)>;
				slew-rate = "very-high-speed";
			};

			/omit-if-no-ref/ octospi1_io7_pg14: octospi1_io7_pg14 {
				pinmux = <STM32_PINMUX('G', 14, AF9)>;
				slew-rate = "very-high-speed";
			};

			/omit-if-no-ref/ octospi1_io4_ph2: octospi1_io4_ph2 {
				pinmux = <STM32_PINMUX('H', 2, AF9)>;
				slew-rate = "very-high-speed";
			};

			/omit-if-no-ref/ octospi1_io5_ph3: octospi1_io5_ph3 {
				pinmux = <STM32_PINMUX('H', 3, AF9)>;
				slew-rate = "very-high-speed";
			};

			/* RCC_MCO */

			/omit-if-no-ref/ rcc_mco_1_pa8: rcc_mco_1_pa8 {
				pinmux = <STM32_PINMUX('A', 8, AF0)>;
				slew-rate = "very-high-speed";
			};

			/omit-if-no-ref/ rcc_mco_2_pc9: rcc_mco_2_pc9 {
				pinmux = <STM32_PINMUX('C', 9, AF0)>;
				slew-rate = "very-high-speed";
			};

			/* SAI */

			/omit-if-no-ref/ sai1_sd_b_pa3: sai1_sd_b_pa3 {
				pinmux = <STM32_PINMUX('A', 3, AF6)>;
			};

			/omit-if-no-ref/ sai1_d1_pb2: sai1_d1_pb2 {
				pinmux = <STM32_PINMUX('B', 2, AF2)>;
			};

			/omit-if-no-ref/ sai1_sd_a_pb2: sai1_sd_a_pb2 {
				pinmux = <STM32_PINMUX('B', 2, AF6)>;
			};

			/omit-if-no-ref/ sai1_mclk_a_pc0: sai1_mclk_a_pc0 {
				pinmux = <STM32_PINMUX('C', 0, AF6)>;
			};

			/omit-if-no-ref/ sai1_d1_pc1: sai1_d1_pc1 {
				pinmux = <STM32_PINMUX('C', 1, AF2)>;
			};

			/omit-if-no-ref/ sai1_sd_a_pc1: sai1_sd_a_pc1 {
				pinmux = <STM32_PINMUX('C', 1, AF6)>;
			};

			/omit-if-no-ref/ sai1_d3_pc3: sai1_d3_pc3 {
				pinmux = <STM32_PINMUX('C', 3, AF2)>;
			};

			/omit-if-no-ref/ sai1_ck1_pc4: sai1_ck1_pc4 {
				pinmux = <STM32_PINMUX('C', 4, AF2)>;
			};

			/omit-if-no-ref/ sai1_d3_pc5: sai1_d3_pc5 {
				pinmux = <STM32_PINMUX('C', 5, AF2)>;
			};

			/omit-if-no-ref/ sai1_fs_a_pc5: sai1_fs_a_pc5 {
				pinmux = <STM32_PINMUX('C', 5, AF6)>;
			};

			/omit-if-no-ref/ sai1_sck_a_pc6: sai1_sck_a_pc6 {
				pinmux = <STM32_PINMUX('C', 6, AF6)>;
			};

			/omit-if-no-ref/ sai1_d1_pd6: sai1_d1_pd6 {
				pinmux = <STM32_PINMUX('D', 6, AF2)>;
			};

			/omit-if-no-ref/ sai1_sd_a_pd6: sai1_sd_a_pd6 {
				pinmux = <STM32_PINMUX('D', 6, AF6)>;
			};

			/omit-if-no-ref/ sai1_ck1_pd11: sai1_ck1_pd11 {
				pinmux = <STM32_PINMUX('D', 11, AF2)>;
			};

			/omit-if-no-ref/ sai1_d1_pd12: sai1_d1_pd12 {
				pinmux = <STM32_PINMUX('D', 12, AF6)>;
			};

			/omit-if-no-ref/ sai1_ck1_pe2: sai1_ck1_pe2 {
				pinmux = <STM32_PINMUX('E', 2, AF2)>;
			};

			/omit-if-no-ref/ sai1_mclk_a_pe2: sai1_mclk_a_pe2 {
				pinmux = <STM32_PINMUX('E', 2, AF6)>;
			};

			/omit-if-no-ref/ sai1_sd_b_pe3: sai1_sd_b_pe3 {
				pinmux = <STM32_PINMUX('E', 3, AF6)>;
			};

			/omit-if-no-ref/ sai1_d2_pe4: sai1_d2_pe4 {
				pinmux = <STM32_PINMUX('E', 4, AF2)>;
			};

			/omit-if-no-ref/ sai1_fs_a_pe4: sai1_fs_a_pe4 {
				pinmux = <STM32_PINMUX('E', 4, AF6)>;
			};

			/omit-if-no-ref/ sai1_ck2_pe5: sai1_ck2_pe5 {
				pinmux = <STM32_PINMUX('E', 5, AF2)>;
			};

			/omit-if-no-ref/ sai1_sck_a_pe5: sai1_sck_a_pe5 {
				pinmux = <STM32_PINMUX('E', 5, AF6)>;
			};

			/omit-if-no-ref/ sai1_d1_pe6: sai1_d1_pe6 {
				pinmux = <STM32_PINMUX('E', 6, AF2)>;
			};

			/omit-if-no-ref/ sai1_sd_a_pe6: sai1_sd_a_pe6 {
				pinmux = <STM32_PINMUX('E', 6, AF6)>;
			};

			/omit-if-no-ref/ sai1_sd_b_pf6: sai1_sd_b_pf6 {
				pinmux = <STM32_PINMUX('F', 6, AF6)>;
			};

			/omit-if-no-ref/ sai1_mclk_b_pf7: sai1_mclk_b_pf7 {
				pinmux = <STM32_PINMUX('F', 7, AF6)>;
			};

			/omit-if-no-ref/ sai1_sck_b_pf8: sai1_sck_b_pf8 {
				pinmux = <STM32_PINMUX('F', 8, AF6)>;
			};

			/omit-if-no-ref/ sai1_fs_b_pf9: sai1_fs_b_pf9 {
				pinmux = <STM32_PINMUX('F', 9, AF6)>;
			};

			/omit-if-no-ref/ sai1_d3_pf10: sai1_d3_pf10 {
				pinmux = <STM32_PINMUX('F', 10, AF2)>;
			};

			/omit-if-no-ref/ sai1_ck2_pg7: sai1_ck2_pg7 {
				pinmux = <STM32_PINMUX('G', 7, AF2)>;
			};

			/omit-if-no-ref/ sai1_mclk_a_pg7: sai1_mclk_a_pg7 {
				pinmux = <STM32_PINMUX('G', 7, AF6)>;
			};

			/omit-if-no-ref/ sai2_sd_b_pa0: sai2_sd_b_pa0 {
				pinmux = <STM32_PINMUX('A', 0, AF10)>;
			};

			/omit-if-no-ref/ sai2_mclk_b_pa1: sai2_mclk_b_pa1 {
				pinmux = <STM32_PINMUX('A', 1, AF10)>;
			};

			/omit-if-no-ref/ sai2_sck_b_pa2: sai2_sck_b_pa2 {
				pinmux = <STM32_PINMUX('A', 2, AF8)>;
			};

			/omit-if-no-ref/ sai2_fs_b_pa12: sai2_fs_b_pa12 {
				pinmux = <STM32_PINMUX('A', 12, AF8)>;
			};

			/omit-if-no-ref/ sai2_fs_b_pc0: sai2_fs_b_pc0 {
				pinmux = <STM32_PINMUX('C', 0, AF8)>;
			};

			/omit-if-no-ref/ sai2_sd_a_pc1: sai2_sd_a_pc1 {
				pinmux = <STM32_PINMUX('C', 1, AF8)>;
			};

			/omit-if-no-ref/ sai2_sd_a_pd11: sai2_sd_a_pd11 {
				pinmux = <STM32_PINMUX('D', 11, AF10)>;
			};

			/omit-if-no-ref/ sai2_fs_a_pd12: sai2_fs_a_pd12 {
				pinmux = <STM32_PINMUX('D', 12, AF10)>;
			};

			/omit-if-no-ref/ sai2_sck_a_pd13: sai2_sck_a_pd13 {
				pinmux = <STM32_PINMUX('D', 13, AF10)>;
			};

			/omit-if-no-ref/ sai2_mclk_a_pe0: sai2_mclk_a_pe0 {
				pinmux = <STM32_PINMUX('E', 0, AF10)>;
			};

			/omit-if-no-ref/ sai2_mclk_b_pe6: sai2_mclk_b_pe6 {
				pinmux = <STM32_PINMUX('E', 6, AF10)>;
			};

			/omit-if-no-ref/ sai2_sd_b_pe11: sai2_sd_b_pe11 {
				pinmux = <STM32_PINMUX('E', 11, AF10)>;
			};

			/omit-if-no-ref/ sai2_sck_b_pe12: sai2_sck_b_pe12 {
				pinmux = <STM32_PINMUX('E', 12, AF10)>;
			};

			/omit-if-no-ref/ sai2_fs_b_pe13: sai2_fs_b_pe13 {
				pinmux = <STM32_PINMUX('E', 13, AF10)>;
			};

			/omit-if-no-ref/ sai2_mclk_b_pe14: sai2_mclk_b_pe14 {
				pinmux = <STM32_PINMUX('E', 14, AF10)>;
			};

			/omit-if-no-ref/ sai2_sd_b_pf11: sai2_sd_b_pf11 {
				pinmux = <STM32_PINMUX('F', 11, AF10)>;
			};

			/omit-if-no-ref/ sai2_fs_b_pg9: sai2_fs_b_pg9 {
				pinmux = <STM32_PINMUX('G', 9, AF10)>;
			};

			/omit-if-no-ref/ sai2_sd_b_pg10: sai2_sd_b_pg10 {
				pinmux = <STM32_PINMUX('G', 10, AF10)>;
			};

			/omit-if-no-ref/ sai2_sck_b_ph2: sai2_sck_b_ph2 {
				pinmux = <STM32_PINMUX('H', 2, AF10)>;
			};

			/omit-if-no-ref/ sai2_mclk_b_ph3: sai2_mclk_b_ph3 {
				pinmux = <STM32_PINMUX('H', 3, AF10)>;
			};

			/omit-if-no-ref/ sai2_mclk_a_pi4: sai2_mclk_a_pi4 {
				pinmux = <STM32_PINMUX('I', 4, AF10)>;
			};

			/omit-if-no-ref/ sai2_sd_a_pi6: sai2_sd_a_pi6 {
				pinmux = <STM32_PINMUX('I', 6, AF10)>;
			};

			/omit-if-no-ref/ sai2_fs_a_pi7: sai2_fs_a_pi7 {
				pinmux = <STM32_PINMUX('I', 7, AF10)>;
			};

			/* SDMMC */

			/omit-if-no-ref/ sdmmc1_d0_pa10: sdmmc1_d0_pa10 {
				pinmux = <STM32_PINMUX('A', 10, AF12)>;
				bias-pull-up;
				slew-rate = "very-high-speed";
			};

			/omit-if-no-ref/ sdmmc1_cmd_pb2: sdmmc1_cmd_pb2 {
				pinmux = <STM32_PINMUX('B', 2, AF12)>;
				bias-pull-up;
				slew-rate = "very-high-speed";
			};

			/omit-if-no-ref/ sdmmc1_ckin_pb8: sdmmc1_ckin_pb8 {
				pinmux = <STM32_PINMUX('B', 8, AF7)>;
				bias-pull-up;
				slew-rate = "very-high-speed";
			};

			/omit-if-no-ref/ sdmmc1_d4_pb8: sdmmc1_d4_pb8 {
				pinmux = <STM32_PINMUX('B', 8, AF12)>;
				bias-pull-up;
				slew-rate = "very-high-speed";
			};

			/omit-if-no-ref/ sdmmc1_cdir_pb9: sdmmc1_cdir_pb9 {
				pinmux = <STM32_PINMUX('B', 9, AF7)>;
				bias-pull-up;
				slew-rate = "very-high-speed";
			};

			/omit-if-no-ref/ sdmmc1_d5_pb9: sdmmc1_d5_pb9 {
				pinmux = <STM32_PINMUX('B', 9, AF12)>;
				bias-pull-up;
				slew-rate = "very-high-speed";
			};

			/omit-if-no-ref/ sdmmc1_d0_pb13: sdmmc1_d0_pb13 {
				pinmux = <STM32_PINMUX('B', 13, AF12)>;
				bias-pull-up;
				slew-rate = "very-high-speed";
			};

			/omit-if-no-ref/ sdmmc1_d0dir_pc6: sdmmc1_d0dir_pc6 {
				pinmux = <STM32_PINMUX('C', 6, AF8)>;
				bias-pull-up;
				slew-rate = "very-high-speed";
			};

			/omit-if-no-ref/ sdmmc1_d6_pc6: sdmmc1_d6_pc6 {
				pinmux = <STM32_PINMUX('C', 6, AF12)>;
				bias-pull-up;
				slew-rate = "very-high-speed";
			};

			/omit-if-no-ref/ sdmmc1_d123dir_pc7: sdmmc1_d123dir_pc7 {
				pinmux = <STM32_PINMUX('C', 7, AF8)>;
				bias-pull-up;
				slew-rate = "very-high-speed";
			};

			/omit-if-no-ref/ sdmmc1_d7_pc7: sdmmc1_d7_pc7 {
				pinmux = <STM32_PINMUX('C', 7, AF12)>;
				bias-pull-up;
				slew-rate = "very-high-speed";
			};

			/omit-if-no-ref/ sdmmc1_d0_pc8: sdmmc1_d0_pc8 {
				pinmux = <STM32_PINMUX('C', 8, AF12)>;
				bias-pull-up;
				slew-rate = "very-high-speed";
			};

			/omit-if-no-ref/ sdmmc1_d1_pc9: sdmmc1_d1_pc9 {
				pinmux = <STM32_PINMUX('C', 9, AF12)>;
				bias-pull-up;
				slew-rate = "very-high-speed";
			};

			/omit-if-no-ref/ sdmmc1_d2_pc10: sdmmc1_d2_pc10 {
				pinmux = <STM32_PINMUX('C', 10, AF12)>;
				bias-pull-up;
				slew-rate = "very-high-speed";
			};

			/omit-if-no-ref/ sdmmc1_d3_pc11: sdmmc1_d3_pc11 {
				pinmux = <STM32_PINMUX('C', 11, AF12)>;
				bias-pull-up;
				slew-rate = "very-high-speed";
			};

			/omit-if-no-ref/ sdmmc1_ck_pc12: sdmmc1_ck_pc12 {
				pinmux = <STM32_PINMUX('C', 12, AF12)>;
				bias-pull-up;
				slew-rate = "very-high-speed";
			};

			/omit-if-no-ref/ sdmmc1_cmd_pd2: sdmmc1_cmd_pd2 {
				pinmux = <STM32_PINMUX('D', 2, AF12)>;
				bias-pull-up;
				slew-rate = "very-high-speed";
			};

			/omit-if-no-ref/ sdmmc2_cmd_pa0: sdmmc2_cmd_pa0 {
				pinmux = <STM32_PINMUX('A', 0, AF9)>;
				bias-pull-up;
				slew-rate = "very-high-speed";
			};

			/omit-if-no-ref/ sdmmc2_d2_pb3: sdmmc2_d2_pb3 {
				pinmux = <STM32_PINMUX('B', 3, AF9)>;
				bias-pull-up;
				slew-rate = "very-high-speed";
			};

			/omit-if-no-ref/ sdmmc2_d3_pb4: sdmmc2_d3_pb4 {
				pinmux = <STM32_PINMUX('B', 4, AF9)>;
				bias-pull-up;
				slew-rate = "very-high-speed";
			};

			/omit-if-no-ref/ sdmmc2_ckin_pb7: sdmmc2_ckin_pb7 {
				pinmux = <STM32_PINMUX('B', 7, AF11)>;
				bias-pull-up;
				slew-rate = "very-high-speed";
			};

			/omit-if-no-ref/ sdmmc2_d5_pb7: sdmmc2_d5_pb7 {
				pinmux = <STM32_PINMUX('B', 7, AF10)>;
				bias-pull-up;
				slew-rate = "very-high-speed";
			};

			/omit-if-no-ref/ sdmmc2_d4_pb8: sdmmc2_d4_pb8 {
				pinmux = <STM32_PINMUX('B', 8, AF10)>;
				bias-pull-up;
				slew-rate = "very-high-speed";
			};

			/omit-if-no-ref/ sdmmc2_ckin_pb9: sdmmc2_ckin_pb9 {
				pinmux = <STM32_PINMUX('B', 9, AF11)>;
				bias-pull-up;
				slew-rate = "very-high-speed";
			};

			/omit-if-no-ref/ sdmmc2_d5_pb9: sdmmc2_d5_pb9 {
				pinmux = <STM32_PINMUX('B', 9, AF10)>;
				bias-pull-up;
				slew-rate = "very-high-speed";
			};

			/omit-if-no-ref/ sdmmc2_d0_pb14: sdmmc2_d0_pb14 {
				pinmux = <STM32_PINMUX('B', 14, AF9)>;
				bias-pull-up;
				slew-rate = "very-high-speed";
			};

			/omit-if-no-ref/ sdmmc2_d1_pb15: sdmmc2_d1_pb15 {
				pinmux = <STM32_PINMUX('B', 15, AF9)>;
				bias-pull-up;
				slew-rate = "very-high-speed";
			};

			/omit-if-no-ref/ sdmmc2_ck_pc1: sdmmc2_ck_pc1 {
				pinmux = <STM32_PINMUX('C', 1, AF9)>;
				bias-pull-up;
				slew-rate = "very-high-speed";
			};

			/omit-if-no-ref/ sdmmc2_d6_pc6: sdmmc2_d6_pc6 {
				pinmux = <STM32_PINMUX('C', 6, AF10)>;
				bias-pull-up;
				slew-rate = "very-high-speed";
			};

			/omit-if-no-ref/ sdmmc2_d7_pc7: sdmmc2_d7_pc7 {
				pinmux = <STM32_PINMUX('C', 7, AF10)>;
				bias-pull-up;
				slew-rate = "very-high-speed";
			};

			/omit-if-no-ref/ sdmmc2_ck_pd6: sdmmc2_ck_pd6 {
				pinmux = <STM32_PINMUX('D', 6, AF11)>;
				bias-pull-up;
				slew-rate = "very-high-speed";
			};

			/omit-if-no-ref/ sdmmc2_cmd_pd7: sdmmc2_cmd_pd7 {
				pinmux = <STM32_PINMUX('D', 7, AF11)>;
				bias-pull-up;
				slew-rate = "very-high-speed";
			};

			/omit-if-no-ref/ sdmmc2_d0_pg9: sdmmc2_d0_pg9 {
				pinmux = <STM32_PINMUX('G', 9, AF11)>;
				bias-pull-up;
				slew-rate = "very-high-speed";
			};

			/omit-if-no-ref/ sdmmc2_d1_pg10: sdmmc2_d1_pg10 {
				pinmux = <STM32_PINMUX('G', 10, AF11)>;
				bias-pull-up;
				slew-rate = "very-high-speed";
			};

			/omit-if-no-ref/ sdmmc2_d2_pg11: sdmmc2_d2_pg11 {
				pinmux = <STM32_PINMUX('G', 11, AF10)>;
				bias-pull-up;
				slew-rate = "very-high-speed";
			};

			/omit-if-no-ref/ sdmmc2_d3_pg12: sdmmc2_d3_pg12 {
				pinmux = <STM32_PINMUX('G', 12, AF10)>;
				bias-pull-up;
				slew-rate = "very-high-speed";
			};

			/omit-if-no-ref/ sdmmc2_d6_pg13: sdmmc2_d6_pg13 {
				pinmux = <STM32_PINMUX('G', 13, AF10)>;
				bias-pull-up;
				slew-rate = "very-high-speed";
			};

			/omit-if-no-ref/ sdmmc2_d7_pg14: sdmmc2_d7_pg14 {
				pinmux = <STM32_PINMUX('G', 14, AF10)>;
				bias-pull-up;
				slew-rate = "very-high-speed";
			};

			/* SPI_MISO */

			/omit-if-no-ref/ spi1_miso_pa6: spi1_miso_pa6 {
				pinmux = <STM32_PINMUX('A', 6, AF5)>;
				bias-pull-down;
			};

			/omit-if-no-ref/ spi1_miso_pb4: spi1_miso_pb4 {
				pinmux = <STM32_PINMUX('B', 4, AF5)>;
				bias-pull-down;
			};

			/omit-if-no-ref/ spi1_miso_pg9: spi1_miso_pg9 {
				pinmux = <STM32_PINMUX('G', 9, AF5)>;
				bias-pull-down;
			};

			/omit-if-no-ref/ spi2_miso_pb14: spi2_miso_pb14 {
				pinmux = <STM32_PINMUX('B', 14, AF5)>;
				bias-pull-down;
			};

			/omit-if-no-ref/ spi2_miso_pc2: spi2_miso_pc2 {
				pinmux = <STM32_PINMUX('C', 2, AF5)>;
				bias-pull-down;
			};

			/omit-if-no-ref/ spi2_miso_pi2: spi2_miso_pi2 {
				pinmux = <STM32_PINMUX('I', 2, AF5)>;
				bias-pull-down;
			};

			/omit-if-no-ref/ spi3_miso_pb4: spi3_miso_pb4 {
				pinmux = <STM32_PINMUX('B', 4, AF6)>;
				bias-pull-down;
			};

			/omit-if-no-ref/ spi3_miso_pc11: spi3_miso_pc11 {
				pinmux = <STM32_PINMUX('C', 11, AF6)>;
				bias-pull-down;
			};

			/omit-if-no-ref/ spi4_miso_pe5: spi4_miso_pe5 {
				pinmux = <STM32_PINMUX('E', 5, AF5)>;
				bias-pull-down;
			};

			/omit-if-no-ref/ spi4_miso_pe13: spi4_miso_pe13 {
				pinmux = <STM32_PINMUX('E', 13, AF5)>;
				bias-pull-down;
			};

			/omit-if-no-ref/ spi5_miso_pf8: spi5_miso_pf8 {
				pinmux = <STM32_PINMUX('F', 8, AF5)>;
				bias-pull-down;
			};

			/omit-if-no-ref/ spi5_miso_ph7: spi5_miso_ph7 {
				pinmux = <STM32_PINMUX('H', 7, AF5)>;
				bias-pull-down;
			};

			/omit-if-no-ref/ spi6_miso_pa6: spi6_miso_pa6 {
				pinmux = <STM32_PINMUX('A', 6, AF8)>;
				bias-pull-down;
			};

			/omit-if-no-ref/ spi6_miso_pb4: spi6_miso_pb4 {
				pinmux = <STM32_PINMUX('B', 4, AF8)>;
				bias-pull-down;
			};

			/omit-if-no-ref/ spi6_miso_pg12: spi6_miso_pg12 {
				pinmux = <STM32_PINMUX('G', 12, AF5)>;
				bias-pull-down;
			};

			/* SPI_MOSI */

			/omit-if-no-ref/ spi1_mosi_pa7: spi1_mosi_pa7 {
				pinmux = <STM32_PINMUX('A', 7, AF5)>;
				bias-pull-down;
			};

			/omit-if-no-ref/ spi1_mosi_pb5: spi1_mosi_pb5 {
				pinmux = <STM32_PINMUX('B', 5, AF5)>;
				bias-pull-down;
			};

			/omit-if-no-ref/ spi1_mosi_pd7: spi1_mosi_pd7 {
				pinmux = <STM32_PINMUX('D', 7, AF5)>;
				bias-pull-down;
			};

			/omit-if-no-ref/ spi2_mosi_pb15: spi2_mosi_pb15 {
				pinmux = <STM32_PINMUX('B', 15, AF5)>;
				bias-pull-down;
			};

			/omit-if-no-ref/ spi2_mosi_pc1: spi2_mosi_pc1 {
				pinmux = <STM32_PINMUX('C', 1, AF5)>;
				bias-pull-down;
			};

			/omit-if-no-ref/ spi2_mosi_pc3: spi2_mosi_pc3 {
				pinmux = <STM32_PINMUX('C', 3, AF5)>;
				bias-pull-down;
			};

			/omit-if-no-ref/ spi2_mosi_pg1: spi2_mosi_pg1 {
				pinmux = <STM32_PINMUX('G', 1, AF7)>;
				bias-pull-down;
			};

			/omit-if-no-ref/ spi2_mosi_pi3: spi2_mosi_pi3 {
				pinmux = <STM32_PINMUX('I', 3, AF5)>;
				bias-pull-down;
			};

			/omit-if-no-ref/ spi3_mosi_pb2: spi3_mosi_pb2 {
				pinmux = <STM32_PINMUX('B', 2, AF7)>;
				bias-pull-down;
			};

			/omit-if-no-ref/ spi3_mosi_pb5: spi3_mosi_pb5 {
				pinmux = <STM32_PINMUX('B', 5, AF7)>;
				bias-pull-down;
			};

			/omit-if-no-ref/ spi3_mosi_pc12: spi3_mosi_pc12 {
				pinmux = <STM32_PINMUX('C', 12, AF6)>;
				bias-pull-down;
			};

			/omit-if-no-ref/ spi3_mosi_pd6: spi3_mosi_pd6 {
				pinmux = <STM32_PINMUX('D', 6, AF5)>;
				bias-pull-down;
			};

			/omit-if-no-ref/ spi4_mosi_pe6: spi4_mosi_pe6 {
				pinmux = <STM32_PINMUX('E', 6, AF5)>;
				bias-pull-down;
			};

			/omit-if-no-ref/ spi4_mosi_pe14: spi4_mosi_pe14 {
				pinmux = <STM32_PINMUX('E', 14, AF5)>;
				bias-pull-down;
			};

			/omit-if-no-ref/ spi5_mosi_pf9: spi5_mosi_pf9 {
				pinmux = <STM32_PINMUX('F', 9, AF5)>;
				bias-pull-down;
			};

			/omit-if-no-ref/ spi5_mosi_pf11: spi5_mosi_pf11 {
				pinmux = <STM32_PINMUX('F', 11, AF5)>;
				bias-pull-down;
			};

			/omit-if-no-ref/ spi5_mosi_ph8: spi5_mosi_ph8 {
				pinmux = <STM32_PINMUX('H', 8, AF5)>;
				bias-pull-down;
			};

			/omit-if-no-ref/ spi6_mosi_pa7: spi6_mosi_pa7 {
				pinmux = <STM32_PINMUX('A', 7, AF8)>;
				bias-pull-down;
			};

			/omit-if-no-ref/ spi6_mosi_pb5: spi6_mosi_pb5 {
				pinmux = <STM32_PINMUX('B', 5, AF8)>;
				bias-pull-down;
			};

			/omit-if-no-ref/ spi6_mosi_pg14: spi6_mosi_pg14 {
				pinmux = <STM32_PINMUX('G', 14, AF5)>;
				bias-pull-down;
			};

			/* SPI_NSS */

			/omit-if-no-ref/ spi1_nss_pa4: spi1_nss_pa4 {
				pinmux = <STM32_PINMUX('A', 4, AF5)>;
				bias-pull-up;
			};

			/omit-if-no-ref/ spi1_nss_pa15: spi1_nss_pa15 {
				pinmux = <STM32_PINMUX('A', 15, AF5)>;
				bias-pull-up;
			};

			/omit-if-no-ref/ spi1_nss_pg10: spi1_nss_pg10 {
				pinmux = <STM32_PINMUX('G', 10, AF5)>;
				bias-pull-up;
			};

			/omit-if-no-ref/ spi2_nss_pa3: spi2_nss_pa3 {
				pinmux = <STM32_PINMUX('A', 3, AF5)>;
				bias-pull-up;
			};

			/omit-if-no-ref/ spi2_nss_pa11: spi2_nss_pa11 {
				pinmux = <STM32_PINMUX('A', 11, AF5)>;
				bias-pull-up;
			};

			/omit-if-no-ref/ spi2_nss_pb4: spi2_nss_pb4 {
				pinmux = <STM32_PINMUX('B', 4, AF7)>;
				bias-pull-up;
			};

			/omit-if-no-ref/ spi2_nss_pb9: spi2_nss_pb9 {
				pinmux = <STM32_PINMUX('B', 9, AF5)>;
				bias-pull-up;
			};

			/omit-if-no-ref/ spi2_nss_pb12: spi2_nss_pb12 {
				pinmux = <STM32_PINMUX('B', 12, AF5)>;
				bias-pull-up;
			};

			/omit-if-no-ref/ spi2_nss_pi0: spi2_nss_pi0 {
				pinmux = <STM32_PINMUX('I', 0, AF5)>;
				bias-pull-up;
			};

			/omit-if-no-ref/ spi3_nss_pa4: spi3_nss_pa4 {
				pinmux = <STM32_PINMUX('A', 4, AF6)>;
				bias-pull-up;
			};

			/omit-if-no-ref/ spi3_nss_pa15: spi3_nss_pa15 {
				pinmux = <STM32_PINMUX('A', 15, AF6)>;
				bias-pull-up;
			};

			/omit-if-no-ref/ spi4_nss_pe4: spi4_nss_pe4 {
				pinmux = <STM32_PINMUX('E', 4, AF5)>;
				bias-pull-up;
			};

			/omit-if-no-ref/ spi4_nss_pe11: spi4_nss_pe11 {
				pinmux = <STM32_PINMUX('E', 11, AF5)>;
				bias-pull-up;
			};

			/omit-if-no-ref/ spi5_nss_pf6: spi5_nss_pf6 {
				pinmux = <STM32_PINMUX('F', 6, AF5)>;
				bias-pull-up;
			};

			/omit-if-no-ref/ spi5_nss_ph5: spi5_nss_ph5 {
				pinmux = <STM32_PINMUX('H', 5, AF5)>;
				bias-pull-up;
			};

			/omit-if-no-ref/ spi6_nss_pa0: spi6_nss_pa0 {
				pinmux = <STM32_PINMUX('A', 0, AF5)>;
				bias-pull-up;
			};

			/omit-if-no-ref/ spi6_nss_pa4: spi6_nss_pa4 {
				pinmux = <STM32_PINMUX('A', 4, AF8)>;
				bias-pull-up;
			};

			/omit-if-no-ref/ spi6_nss_pa15: spi6_nss_pa15 {
				pinmux = <STM32_PINMUX('A', 15, AF7)>;
				bias-pull-up;
			};

			/omit-if-no-ref/ spi6_nss_pg8: spi6_nss_pg8 {
				pinmux = <STM32_PINMUX('G', 8, AF5)>;
				bias-pull-up;
			};

			/* SPI_SCK */

			/omit-if-no-ref/ spi1_sck_pa5: spi1_sck_pa5 {
				pinmux = <STM32_PINMUX('A', 5, AF5)>;
				bias-pull-down;
				slew-rate = "very-high-speed";
			};

			/omit-if-no-ref/ spi1_sck_pb3: spi1_sck_pb3 {
				pinmux = <STM32_PINMUX('B', 3, AF5)>;
				bias-pull-down;
				slew-rate = "very-high-speed";
			};

			/omit-if-no-ref/ spi1_sck_pg11: spi1_sck_pg11 {
				pinmux = <STM32_PINMUX('G', 11, AF5)>;
				bias-pull-down;
				slew-rate = "very-high-speed";
			};

			/omit-if-no-ref/ spi2_sck_pa9: spi2_sck_pa9 {
				pinmux = <STM32_PINMUX('A', 9, AF5)>;
				bias-pull-down;
				slew-rate = "very-high-speed";
			};

			/omit-if-no-ref/ spi2_sck_pa12: spi2_sck_pa12 {
				pinmux = <STM32_PINMUX('A', 12, AF5)>;
				bias-pull-down;
				slew-rate = "very-high-speed";
			};

			/omit-if-no-ref/ spi2_sck_pb10: spi2_sck_pb10 {
				pinmux = <STM32_PINMUX('B', 10, AF5)>;
				bias-pull-down;
				slew-rate = "very-high-speed";
			};

			/omit-if-no-ref/ spi2_sck_pb13: spi2_sck_pb13 {
				pinmux = <STM32_PINMUX('B', 13, AF5)>;
				bias-pull-down;
				slew-rate = "very-high-speed";
			};

			/omit-if-no-ref/ spi2_sck_pd3: spi2_sck_pd3 {
				pinmux = <STM32_PINMUX('D', 3, AF5)>;
				bias-pull-down;
				slew-rate = "very-high-speed";
			};

			/omit-if-no-ref/ spi2_sck_pi1: spi2_sck_pi1 {
				pinmux = <STM32_PINMUX('I', 1, AF5)>;
				bias-pull-down;
				slew-rate = "very-high-speed";
			};

			/omit-if-no-ref/ spi3_sck_pb3: spi3_sck_pb3 {
				pinmux = <STM32_PINMUX('B', 3, AF6)>;
				bias-pull-down;
				slew-rate = "very-high-speed";
			};

			/omit-if-no-ref/ spi3_sck_pc10: spi3_sck_pc10 {
				pinmux = <STM32_PINMUX('C', 10, AF6)>;
				bias-pull-down;
				slew-rate = "very-high-speed";
			};

			/omit-if-no-ref/ spi4_sck_pe2: spi4_sck_pe2 {
				pinmux = <STM32_PINMUX('E', 2, AF5)>;
				bias-pull-down;
				slew-rate = "very-high-speed";
			};

			/omit-if-no-ref/ spi4_sck_pe12: spi4_sck_pe12 {
				pinmux = <STM32_PINMUX('E', 12, AF5)>;
				bias-pull-down;
				slew-rate = "very-high-speed";
			};

			/omit-if-no-ref/ spi5_sck_pf7: spi5_sck_pf7 {
				pinmux = <STM32_PINMUX('F', 7, AF5)>;
				bias-pull-down;
				slew-rate = "very-high-speed";
			};

			/omit-if-no-ref/ spi5_sck_ph6: spi5_sck_ph6 {
				pinmux = <STM32_PINMUX('H', 6, AF5)>;
				bias-pull-down;
				slew-rate = "very-high-speed";
			};

			/omit-if-no-ref/ spi6_sck_pa5: spi6_sck_pa5 {
				pinmux = <STM32_PINMUX('A', 5, AF8)>;
				bias-pull-down;
				slew-rate = "very-high-speed";
			};

			/omit-if-no-ref/ spi6_sck_pb3: spi6_sck_pb3 {
				pinmux = <STM32_PINMUX('B', 3, AF8)>;
				bias-pull-down;
				slew-rate = "very-high-speed";
			};

			/omit-if-no-ref/ spi6_sck_pc12: spi6_sck_pc12 {
				pinmux = <STM32_PINMUX('C', 12, AF5)>;
				bias-pull-down;
				slew-rate = "very-high-speed";
			};

			/omit-if-no-ref/ spi6_sck_pg13: spi6_sck_pg13 {
				pinmux = <STM32_PINMUX('G', 13, AF5)>;
				bias-pull-down;
				slew-rate = "very-high-speed";
			};

			/* TIM_BKIN */

			/omit-if-no-ref/ tim1_bkin_pa6: tim1_bkin_pa6 {
				pinmux = <STM32_PINMUX('A', 6, AF1)>;
			};

			/omit-if-no-ref/ tim1_bkin_pb12: tim1_bkin_pb12 {
				pinmux = <STM32_PINMUX('B', 12, AF1)>;
			};

			/omit-if-no-ref/ tim1_bkin2_pe6: tim1_bkin2_pe6 {
				pinmux = <STM32_PINMUX('E', 6, AF1)>;
			};

			/omit-if-no-ref/ tim1_bkin_pe15: tim1_bkin_pe15 {
				pinmux = <STM32_PINMUX('E', 15, AF1)>;
			};

			/omit-if-no-ref/ tim1_bkin2_pg4: tim1_bkin2_pg4 {
				pinmux = <STM32_PINMUX('G', 4, AF1)>;
			};

			/omit-if-no-ref/ tim1_bkin_ph12: tim1_bkin_ph12 {
				pinmux = <STM32_PINMUX('H', 12, AF1)>;
			};

			/omit-if-no-ref/ tim15_bkin_pa0: tim15_bkin_pa0 {
				pinmux = <STM32_PINMUX('A', 0, AF4)>;
			};

			/omit-if-no-ref/ tim15_bkin_pd2: tim15_bkin_pd2 {
				pinmux = <STM32_PINMUX('D', 2, AF4)>;
			};

			/omit-if-no-ref/ tim15_bkin_pe3: tim15_bkin_pe3 {
				pinmux = <STM32_PINMUX('E', 3, AF4)>;
			};

			/omit-if-no-ref/ tim16_bkin_pb4: tim16_bkin_pb4 {
				pinmux = <STM32_PINMUX('B', 4, AF1)>;
			};

			/omit-if-no-ref/ tim16_bkin_pc0: tim16_bkin_pc0 {
				pinmux = <STM32_PINMUX('C', 0, AF1)>;
			};

			/omit-if-no-ref/ tim16_bkin_pf10: tim16_bkin_pf10 {
				pinmux = <STM32_PINMUX('F', 10, AF1)>;
			};

			/omit-if-no-ref/ tim17_bkin_pb5: tim17_bkin_pb5 {
				pinmux = <STM32_PINMUX('B', 5, AF1)>;
			};

			/omit-if-no-ref/ tim17_bkin_pg6: tim17_bkin_pg6 {
				pinmux = <STM32_PINMUX('G', 6, AF1)>;
			};

			/omit-if-no-ref/ tim8_bkin_pa6: tim8_bkin_pa6 {
				pinmux = <STM32_PINMUX('A', 6, AF3)>;
			};

			/omit-if-no-ref/ tim8_bkin2_pa8: tim8_bkin2_pa8 {
				pinmux = <STM32_PINMUX('A', 8, AF3)>;
			};

			/omit-if-no-ref/ tim8_bkin_pg2: tim8_bkin_pg2 {
				pinmux = <STM32_PINMUX('G', 2, AF3)>;
			};

			/omit-if-no-ref/ tim8_bkin2_pg3: tim8_bkin2_pg3 {
				pinmux = <STM32_PINMUX('G', 3, AF3)>;
			};

			/omit-if-no-ref/ tim8_bkin_ph12: tim8_bkin_ph12 {
				pinmux = <STM32_PINMUX('H', 12, AF3)>;
			};

			/omit-if-no-ref/ tim8_bkin2_pi1: tim8_bkin2_pi1 {
				pinmux = <STM32_PINMUX('I', 1, AF3)>;
			};

			/omit-if-no-ref/ tim8_bkin_pi4: tim8_bkin_pi4 {
				pinmux = <STM32_PINMUX('I', 4, AF3)>;
			};

			/* TIM_CH / TIM_CHN */

			/omit-if-no-ref/ tim1_ch1n_pa7: tim1_ch1n_pa7 {
				pinmux = <STM32_PINMUX('A', 7, AF1)>;
			};

			/omit-if-no-ref/ tim1_ch1_pa8: tim1_ch1_pa8 {
				pinmux = <STM32_PINMUX('A', 8, AF1)>;
			};

			/omit-if-no-ref/ tim1_ch2_pa9: tim1_ch2_pa9 {
				pinmux = <STM32_PINMUX('A', 9, AF1)>;
			};

			/omit-if-no-ref/ tim1_ch3_pa10: tim1_ch3_pa10 {
				pinmux = <STM32_PINMUX('A', 10, AF1)>;
			};

			/omit-if-no-ref/ tim1_ch4_pa11: tim1_ch4_pa11 {
				pinmux = <STM32_PINMUX('A', 11, AF1)>;
			};

			/omit-if-no-ref/ tim1_ch2n_pb0: tim1_ch2n_pb0 {
				pinmux = <STM32_PINMUX('B', 0, AF1)>;
			};

			/omit-if-no-ref/ tim1_ch3n_pb1: tim1_ch3n_pb1 {
				pinmux = <STM32_PINMUX('B', 1, AF1)>;
			};

			/omit-if-no-ref/ tim1_ch1n_pb13: tim1_ch1n_pb13 {
				pinmux = <STM32_PINMUX('B', 13, AF1)>;
			};

			/omit-if-no-ref/ tim1_ch2n_pb14: tim1_ch2n_pb14 {
				pinmux = <STM32_PINMUX('B', 14, AF1)>;
			};

			/omit-if-no-ref/ tim1_ch3n_pb15: tim1_ch3n_pb15 {
				pinmux = <STM32_PINMUX('B', 15, AF1)>;
			};

			/omit-if-no-ref/ tim1_ch4n_pc5: tim1_ch4n_pc5 {
				pinmux = <STM32_PINMUX('C', 5, AF1)>;
			};

			/omit-if-no-ref/ tim1_ch4n_pd5: tim1_ch4n_pd5 {
				pinmux = <STM32_PINMUX('D', 5, AF1)>;
			};

			/omit-if-no-ref/ tim1_ch1n_pe8: tim1_ch1n_pe8 {
				pinmux = <STM32_PINMUX('E', 8, AF1)>;
			};

			/omit-if-no-ref/ tim1_ch1_pe9: tim1_ch1_pe9 {
				pinmux = <STM32_PINMUX('E', 9, AF1)>;
			};

			/omit-if-no-ref/ tim1_ch2n_pe10: tim1_ch2n_pe10 {
				pinmux = <STM32_PINMUX('E', 10, AF1)>;
			};

			/omit-if-no-ref/ tim1_ch2_pe11: tim1_ch2_pe11 {
				pinmux = <STM32_PINMUX('E', 11, AF1)>;
			};

			/omit-if-no-ref/ tim1_ch3n_pe12: tim1_ch3n_pe12 {
				pinmux = <STM32_PINMUX('E', 12, AF1)>;
			};

			/omit-if-no-ref/ tim1_ch3_pe13: tim1_ch3_pe13 {
				pinmux = <STM32_PINMUX('E', 13, AF1)>;
			};

			/omit-if-no-ref/ tim1_ch4_pe14: tim1_ch4_pe14 {
				pinmux = <STM32_PINMUX('E', 14, AF1)>;
			};

			/omit-if-no-ref/ tim1_ch4n_pe15: tim1_ch4n_pe15 {
				pinmux = <STM32_PINMUX('E', 15, AF3)>;
			};

			/omit-if-no-ref/ tim1_ch3n_ph6: tim1_ch3n_ph6 {
				pinmux = <STM32_PINMUX('H', 6, AF1)>;
			};

			/omit-if-no-ref/ tim1_ch3_ph7: tim1_ch3_ph7 {
				pinmux = <STM32_PINMUX('H', 7, AF1)>;
			};

			/omit-if-no-ref/ tim1_ch2n_ph8: tim1_ch2n_ph8 {
				pinmux = <STM32_PINMUX('H', 8, AF1)>;
			};

			/omit-if-no-ref/ tim1_ch1n_ph10: tim1_ch1n_ph10 {
				pinmux = <STM32_PINMUX('H', 10, AF1)>;
			};

			/omit-if-no-ref/ tim1_ch1_ph11: tim1_ch1_ph11 {
				pinmux = <STM32_PINMUX('H', 11, AF1)>;
			};

			/omit-if-no-ref/ tim2_ch1_pa0: tim2_ch1_pa0 {
				pinmux = <STM32_PINMUX('A', 0, AF1)>;
			};

			/omit-if-no-ref/ tim2_ch2_pa1: tim2_ch2_pa1 {
				pinmux = <STM32_PINMUX('A', 1, AF1)>;
			};

			/omit-if-no-ref/ tim2_ch3_pa2: tim2_ch3_pa2 {
				pinmux = <STM32_PINMUX('A', 2, AF1)>;
			};

			/omit-if-no-ref/ tim2_ch4_pa3: tim2_ch4_pa3 {
				pinmux = <STM32_PINMUX('A', 3, AF1)>;
			};

			/omit-if-no-ref/ tim2_ch1_pa5: tim2_ch1_pa5 {
				pinmux = <STM32_PINMUX('A', 5, AF1)>;
			};

			/omit-if-no-ref/ tim2_ch1_pa15: tim2_ch1_pa15 {
				pinmux = <STM32_PINMUX('A', 15, AF1)>;
			};

			/omit-if-no-ref/ tim2_ch2_pb3: tim2_ch2_pb3 {
				pinmux = <STM32_PINMUX('B', 3, AF1)>;
			};

			/omit-if-no-ref/ tim2_ch3_pb10: tim2_ch3_pb10 {
				pinmux = <STM32_PINMUX('B', 10, AF1)>;
			};

			/omit-if-no-ref/ tim2_ch4_pb11: tim2_ch4_pb11 {
				pinmux = <STM32_PINMUX('B', 11, AF1)>;
			};

			/omit-if-no-ref/ tim12_ch1_pb14: tim12_ch1_pb14 {
				pinmux = <STM32_PINMUX('B', 14, AF2)>;
			};

			/omit-if-no-ref/ tim12_ch2_pb15: tim12_ch2_pb15 {
				pinmux = <STM32_PINMUX('B', 15, AF2)>;
			};

			/omit-if-no-ref/ tim2_ch4_pc4: tim2_ch4_pc4 {
				pinmux = <STM32_PINMUX('C', 4, AF1)>;
			};

			/omit-if-no-ref/ tim12_ch1_ph6: tim12_ch1_ph6 {
				pinmux = <STM32_PINMUX('H', 6, AF2)>;
			};

			/omit-if-no-ref/ tim13_ch1_pa6: tim13_ch1_pa6 {
				pinmux = <STM32_PINMUX('A', 6, AF9)>;
			};

			/omit-if-no-ref/ tim3_ch1_pa6: tim3_ch1_pa6 {
				pinmux = <STM32_PINMUX('A', 6, AF2)>;
			};

			/omit-if-no-ref/ tim3_ch2_pa7: tim3_ch2_pa7 {
				pinmux = <STM32_PINMUX('A', 7, AF2)>;
			};

			/omit-if-no-ref/ tim3_ch3_pb0: tim3_ch3_pb0 {
				pinmux = <STM32_PINMUX('B', 0, AF2)>;
			};

			/omit-if-no-ref/ tim3_ch4_pb1: tim3_ch4_pb1 {
				pinmux = <STM32_PINMUX('B', 1, AF2)>;
			};

			/omit-if-no-ref/ tim3_ch1_pb4: tim3_ch1_pb4 {
				pinmux = <STM32_PINMUX('B', 4, AF2)>;
			};

			/omit-if-no-ref/ tim3_ch2_pb5: tim3_ch2_pb5 {
				pinmux = <STM32_PINMUX('B', 5, AF2)>;
			};

			/omit-if-no-ref/ tim3_ch1_pc6: tim3_ch1_pc6 {
				pinmux = <STM32_PINMUX('C', 6, AF2)>;
			};

			/omit-if-no-ref/ tim3_ch2_pc7: tim3_ch2_pc7 {
				pinmux = <STM32_PINMUX('C', 7, AF2)>;
			};

			/omit-if-no-ref/ tim3_ch3_pc8: tim3_ch3_pc8 {
				pinmux = <STM32_PINMUX('C', 8, AF2)>;
			};

			/omit-if-no-ref/ tim3_ch4_pc9: tim3_ch4_pc9 {
				pinmux = <STM32_PINMUX('C', 9, AF2)>;
			};

			/omit-if-no-ref/ tim13_ch1_pf8: tim13_ch1_pf8 {
				pinmux = <STM32_PINMUX('F', 8, AF9)>;
			};

			/omit-if-no-ref/ tim14_ch1_pa7: tim14_ch1_pa7 {
				pinmux = <STM32_PINMUX('A', 7, AF9)>;
			};

			/omit-if-no-ref/ tim4_ch1_pb6: tim4_ch1_pb6 {
				pinmux = <STM32_PINMUX('B', 6, AF2)>;
			};

			/omit-if-no-ref/ tim4_ch2_pb7: tim4_ch2_pb7 {
				pinmux = <STM32_PINMUX('B', 7, AF2)>;
			};

			/omit-if-no-ref/ tim4_ch3_pb8: tim4_ch3_pb8 {
				pinmux = <STM32_PINMUX('B', 8, AF2)>;
			};

			/omit-if-no-ref/ tim4_ch4_pb9: tim4_ch4_pb9 {
				pinmux = <STM32_PINMUX('B', 9, AF2)>;
			};

			/omit-if-no-ref/ tim4_ch4_pc2: tim4_ch4_pc2 {
				pinmux = <STM32_PINMUX('C', 2, AF2)>;
			};

			/omit-if-no-ref/ tim4_ch1_pd12: tim4_ch1_pd12 {
				pinmux = <STM32_PINMUX('D', 12, AF2)>;
			};

			/omit-if-no-ref/ tim4_ch2_pd13: tim4_ch2_pd13 {
				pinmux = <STM32_PINMUX('D', 13, AF2)>;
			};

			/omit-if-no-ref/ tim4_ch3_pd14: tim4_ch3_pd14 {
				pinmux = <STM32_PINMUX('D', 14, AF2)>;
			};

			/omit-if-no-ref/ tim4_ch4_pd15: tim4_ch4_pd15 {
				pinmux = <STM32_PINMUX('D', 15, AF2)>;
			};

			/omit-if-no-ref/ tim14_ch1_pf9: tim14_ch1_pf9 {
				pinmux = <STM32_PINMUX('F', 9, AF9)>;
			};

			/omit-if-no-ref/ tim5_ch1_pa0: tim5_ch1_pa0 {
				pinmux = <STM32_PINMUX('A', 0, AF2)>;
			};

			/omit-if-no-ref/ tim15_ch1n_pa1: tim15_ch1n_pa1 {
				pinmux = <STM32_PINMUX('A', 1, AF4)>;
			};

			/omit-if-no-ref/ tim5_ch2_pa1: tim5_ch2_pa1 {
				pinmux = <STM32_PINMUX('A', 1, AF2)>;
			};

			/omit-if-no-ref/ tim15_ch1_pa2: tim15_ch1_pa2 {
				pinmux = <STM32_PINMUX('A', 2, AF4)>;
			};

			/omit-if-no-ref/ tim5_ch3_pa2: tim5_ch3_pa2 {
				pinmux = <STM32_PINMUX('A', 2, AF2)>;
			};

			/omit-if-no-ref/ tim15_ch2_pa3: tim15_ch2_pa3 {
				pinmux = <STM32_PINMUX('A', 3, AF4)>;
			};

			/omit-if-no-ref/ tim5_ch4_pa3: tim5_ch4_pa3 {
				pinmux = <STM32_PINMUX('A', 3, AF2)>;
			};

			/omit-if-no-ref/ tim15_ch1_pc12: tim15_ch1_pc12 {
				pinmux = <STM32_PINMUX('C', 12, AF2)>;
			};

			/omit-if-no-ref/ tim15_ch1n_pe4: tim15_ch1n_pe4 {
				pinmux = <STM32_PINMUX('E', 4, AF4)>;
			};

			/omit-if-no-ref/ tim15_ch1_pe5: tim15_ch1_pe5 {
				pinmux = <STM32_PINMUX('E', 5, AF4)>;
			};

			/omit-if-no-ref/ tim15_ch2_pe6: tim15_ch2_pe6 {
				pinmux = <STM32_PINMUX('E', 6, AF4)>;
			};

			/omit-if-no-ref/ tim5_ch1_ph10: tim5_ch1_ph10 {
				pinmux = <STM32_PINMUX('H', 10, AF2)>;
			};

			/omit-if-no-ref/ tim5_ch2_ph11: tim5_ch2_ph11 {
				pinmux = <STM32_PINMUX('H', 11, AF2)>;
			};

			/omit-if-no-ref/ tim5_ch3_ph12: tim5_ch3_ph12 {
				pinmux = <STM32_PINMUX('H', 12, AF2)>;
			};

			/omit-if-no-ref/ tim5_ch4_pi0: tim5_ch4_pi0 {
				pinmux = <STM32_PINMUX('I', 0, AF2)>;
			};

			/omit-if-no-ref/ tim16_ch1n_pb6: tim16_ch1n_pb6 {
				pinmux = <STM32_PINMUX('B', 6, AF1)>;
			};

			/omit-if-no-ref/ tim16_ch1_pb8: tim16_ch1_pb8 {
				pinmux = <STM32_PINMUX('B', 8, AF1)>;
			};

			/omit-if-no-ref/ tim16_ch1_pf6: tim16_ch1_pf6 {
				pinmux = <STM32_PINMUX('F', 6, AF1)>;
			};

			/omit-if-no-ref/ tim16_ch1n_pf8: tim16_ch1n_pf8 {
				pinmux = <STM32_PINMUX('F', 8, AF1)>;
			};

			/omit-if-no-ref/ tim17_ch1n_pb7: tim17_ch1n_pb7 {
				pinmux = <STM32_PINMUX('B', 7, AF1)>;
			};

			/omit-if-no-ref/ tim17_ch1_pb9: tim17_ch1_pb9 {
				pinmux = <STM32_PINMUX('B', 9, AF1)>;
			};

			/omit-if-no-ref/ tim17_ch1_pc2: tim17_ch1_pc2 {
				pinmux = <STM32_PINMUX('C', 2, AF1)>;
			};

			/omit-if-no-ref/ tim17_ch1_pf7: tim17_ch1_pf7 {
				pinmux = <STM32_PINMUX('F', 7, AF1)>;
			};

			/omit-if-no-ref/ tim17_ch1n_pf9: tim17_ch1n_pf9 {
				pinmux = <STM32_PINMUX('F', 9, AF1)>;
			};

			/omit-if-no-ref/ tim8_ch1n_pa5: tim8_ch1n_pa5 {
				pinmux = <STM32_PINMUX('A', 5, AF3)>;
			};

			/omit-if-no-ref/ tim8_ch1n_pa7: tim8_ch1n_pa7 {
				pinmux = <STM32_PINMUX('A', 7, AF3)>;
			};

			/omit-if-no-ref/ tim8_ch2n_pb0: tim8_ch2n_pb0 {
				pinmux = <STM32_PINMUX('B', 0, AF3)>;
			};

			/omit-if-no-ref/ tim8_ch3n_pb1: tim8_ch3n_pb1 {
				pinmux = <STM32_PINMUX('B', 1, AF3)>;
			};

			/omit-if-no-ref/ tim8_ch4n_pb2: tim8_ch4n_pb2 {
				pinmux = <STM32_PINMUX('B', 2, AF3)>;
			};

			/omit-if-no-ref/ tim8_ch2n_pb14: tim8_ch2n_pb14 {
				pinmux = <STM32_PINMUX('B', 14, AF3)>;
			};

			/omit-if-no-ref/ tim8_ch3n_pb15: tim8_ch3n_pb15 {
				pinmux = <STM32_PINMUX('B', 15, AF3)>;
			};

			/omit-if-no-ref/ tim8_ch1_pc6: tim8_ch1_pc6 {
				pinmux = <STM32_PINMUX('C', 6, AF3)>;
			};

			/omit-if-no-ref/ tim8_ch2_pc7: tim8_ch2_pc7 {
				pinmux = <STM32_PINMUX('C', 7, AF3)>;
			};

			/omit-if-no-ref/ tim8_ch3_pc8: tim8_ch3_pc8 {
				pinmux = <STM32_PINMUX('C', 8, AF3)>;
			};

			/omit-if-no-ref/ tim8_ch4_pc9: tim8_ch4_pc9 {
				pinmux = <STM32_PINMUX('C', 9, AF3)>;
			};

			/omit-if-no-ref/ tim8_ch4n_pd0: tim8_ch4n_pd0 {
				pinmux = <STM32_PINMUX('D', 0, AF3)>;
			};

			/omit-if-no-ref/ tim8_ch1_ph6: tim8_ch1_ph6 {
				pinmux = <STM32_PINMUX('H', 6, AF3)>;
			};

			/omit-if-no-ref/ tim8_ch1n_ph7: tim8_ch1n_ph7 {
				pinmux = <STM32_PINMUX('H', 7, AF3)>;
			};

			/omit-if-no-ref/ tim8_ch2_ph8: tim8_ch2_ph8 {
				pinmux = <STM32_PINMUX('H', 8, AF3)>;
			};

			/omit-if-no-ref/ tim8_ch3_ph10: tim8_ch3_ph10 {
				pinmux = <STM32_PINMUX('H', 10, AF3)>;
			};

			/omit-if-no-ref/ tim8_ch3n_ph11: tim8_ch3n_ph11 {
				pinmux = <STM32_PINMUX('H', 11, AF3)>;
			};

			/omit-if-no-ref/ tim8_ch4n_ph12: tim8_ch4n_ph12 {
				pinmux = <STM32_PINMUX('H', 12, AF10)>;
			};

			/omit-if-no-ref/ tim8_ch1n_ph13: tim8_ch1n_ph13 {
				pinmux = <STM32_PINMUX('H', 13, AF3)>;
			};

			/omit-if-no-ref/ tim8_ch2n_ph14: tim8_ch2n_ph14 {
				pinmux = <STM32_PINMUX('H', 14, AF3)>;
			};

			/omit-if-no-ref/ tim8_ch3n_ph15: tim8_ch3n_ph15 {
				pinmux = <STM32_PINMUX('H', 15, AF3)>;
			};

			/omit-if-no-ref/ tim8_ch4_pi2: tim8_ch4_pi2 {
				pinmux = <STM32_PINMUX('I', 2, AF3)>;
			};

			/omit-if-no-ref/ tim8_ch2_pi6: tim8_ch2_pi6 {
				pinmux = <STM32_PINMUX('I', 6, AF3)>;
			};

			/omit-if-no-ref/ tim8_ch3_pi7: tim8_ch3_pi7 {
				pinmux = <STM32_PINMUX('I', 7, AF3)>;
			};

			/* UART_CTS / USART_CTS / LPUART_CTS */

			/omit-if-no-ref/ usart10_cts_pg13: usart10_cts_pg13 {
				pinmux = <STM32_PINMUX('G', 13, AF6)>;
				bias-pull-up;
			};

			/omit-if-no-ref/ lpuart1_cts_pa11: lpuart1_cts_pa11 {
				pinmux = <STM32_PINMUX('A', 11, AF3)>;
				bias-pull-up;
			};

			/omit-if-no-ref/ usart1_cts_pa11: usart1_cts_pa11 {
				pinmux = <STM32_PINMUX('A', 11, AF7)>;
				bias-pull-up;
			};

			/omit-if-no-ref/ usart11_cts_pb15: usart11_cts_pb15 {
				pinmux = <STM32_PINMUX('B', 15, AF7)>;
				bias-pull-up;
			};

			/omit-if-no-ref/ usart11_cts_pf5: usart11_cts_pf5 {
				pinmux = <STM32_PINMUX('F', 5, AF7)>;
				bias-pull-up;
			};

			/omit-if-no-ref/ usart2_cts_pa0: usart2_cts_pa0 {
				pinmux = <STM32_PINMUX('A', 0, AF7)>;
				bias-pull-up;
			};

			/omit-if-no-ref/ uart12_cts_pb3: uart12_cts_pb3 {
				pinmux = <STM32_PINMUX('B', 3, AF7)>;
				bias-pull-up;
			};

			/omit-if-no-ref/ usart2_cts_pd3: usart2_cts_pd3 {
				pinmux = <STM32_PINMUX('D', 3, AF7)>;
				bias-pull-up;
			};

			/omit-if-no-ref/ uart12_cts_pe8: uart12_cts_pe8 {
				pinmux = <STM32_PINMUX('E', 8, AF6)>;
				bias-pull-up;
			};

			/omit-if-no-ref/ usart3_cts_pb13: usart3_cts_pb13 {
				pinmux = <STM32_PINMUX('B', 13, AF7)>;
				bias-pull-up;
			};

			/omit-if-no-ref/ usart3_cts_pd11: usart3_cts_pd11 {
				pinmux = <STM32_PINMUX('D', 11, AF7)>;
				bias-pull-up;
			};

			/omit-if-no-ref/ uart4_cts_pb0: uart4_cts_pb0 {
				pinmux = <STM32_PINMUX('B', 0, AF8)>;
				bias-pull-up;
			};

			/omit-if-no-ref/ uart4_cts_pb15: uart4_cts_pb15 {
				pinmux = <STM32_PINMUX('B', 15, AF8)>;
				bias-pull-up;
			};

			/omit-if-no-ref/ uart5_cts_pc9: uart5_cts_pc9 {
				pinmux = <STM32_PINMUX('C', 9, AF8)>;
				bias-pull-up;
			};

			/omit-if-no-ref/ usart6_cts_pg13: usart6_cts_pg13 {
				pinmux = <STM32_PINMUX('G', 13, AF7)>;
				bias-pull-up;
			};

			/omit-if-no-ref/ usart6_cts_pg15: usart6_cts_pg15 {
				pinmux = <STM32_PINMUX('G', 15, AF7)>;
				bias-pull-up;
			};

			/omit-if-no-ref/ uart7_cts_pe10: uart7_cts_pe10 {
				pinmux = <STM32_PINMUX('E', 10, AF7)>;
				bias-pull-up;
			};

			/omit-if-no-ref/ uart7_cts_pf9: uart7_cts_pf9 {
				pinmux = <STM32_PINMUX('F', 9, AF7)>;
				bias-pull-up;
			};

			/omit-if-no-ref/ uart8_cts_pd14: uart8_cts_pd14 {
				pinmux = <STM32_PINMUX('D', 14, AF8)>;
				bias-pull-up;
			};

			/omit-if-no-ref/ uart9_cts_pd0: uart9_cts_pd0 {
				pinmux = <STM32_PINMUX('D', 0, AF11)>;
				bias-pull-up;
			};

			/* UART_DE / USART_DE / LPUART_DE */

			/omit-if-no-ref/ usart10_de_pg14: usart10_de_pg14 {
				pinmux = <STM32_PINMUX('G', 14, AF6)>;
				drive-push-pull;
			};

			/omit-if-no-ref/ lpuart1_de_pa12: lpuart1_de_pa12 {
				pinmux = <STM32_PINMUX('A', 12, AF3)>;
				drive-push-pull;
			};

			/omit-if-no-ref/ usart1_de_pa12: usart1_de_pa12 {
				pinmux = <STM32_PINMUX('A', 12, AF7)>;
				drive-push-pull;
			};

			/omit-if-no-ref/ usart11_de_pc1: usart11_de_pc1 {
				pinmux = <STM32_PINMUX('C', 1, AF7)>;
				drive-push-pull;
			};

			/omit-if-no-ref/ usart11_de_pg11: usart11_de_pg11 {
				pinmux = <STM32_PINMUX('G', 11, AF7)>;
				drive-push-pull;
			};

			/omit-if-no-ref/ usart2_de_pa1: usart2_de_pa1 {
				pinmux = <STM32_PINMUX('A', 1, AF7)>;
				drive-push-pull;
			};

			/omit-if-no-ref/ uart12_de_pc5: uart12_de_pc5 {
				pinmux = <STM32_PINMUX('C', 5, AF7)>;
				drive-push-pull;
			};

			/omit-if-no-ref/ usart2_de_pd4: usart2_de_pd4 {
				pinmux = <STM32_PINMUX('D', 4, AF7)>;
				drive-push-pull;
			};

			/omit-if-no-ref/ uart12_de_pe7: uart12_de_pe7 {
				pinmux = <STM32_PINMUX('E', 7, AF6)>;
				drive-push-pull;
			};

			/omit-if-no-ref/ usart3_de_pb14: usart3_de_pb14 {
				pinmux = <STM32_PINMUX('B', 14, AF7)>;
				drive-push-pull;
			};

			/omit-if-no-ref/ usart3_de_pd12: usart3_de_pd12 {
				pinmux = <STM32_PINMUX('D', 12, AF7)>;
				drive-push-pull;
			};

			/omit-if-no-ref/ uart4_de_pa15: uart4_de_pa15 {
				pinmux = <STM32_PINMUX('A', 15, AF8)>;
				drive-push-pull;
			};

			/omit-if-no-ref/ uart4_de_pb14: uart4_de_pb14 {
				pinmux = <STM32_PINMUX('B', 14, AF8)>;
				drive-push-pull;
			};

			/omit-if-no-ref/ uart5_de_pc8: uart5_de_pc8 {
				pinmux = <STM32_PINMUX('C', 8, AF8)>;
				drive-push-pull;
			};

			/omit-if-no-ref/ usart6_de_pg8: usart6_de_pg8 {
				pinmux = <STM32_PINMUX('G', 8, AF7)>;
				drive-push-pull;
			};

			/omit-if-no-ref/ usart6_de_pg12: usart6_de_pg12 {
				pinmux = <STM32_PINMUX('G', 12, AF7)>;
				drive-push-pull;
			};

			/omit-if-no-ref/ uart7_de_pe9: uart7_de_pe9 {
				pinmux = <STM32_PINMUX('E', 9, AF7)>;
				drive-push-pull;
			};

			/omit-if-no-ref/ uart7_de_pf8: uart7_de_pf8 {
				pinmux = <STM32_PINMUX('F', 8, AF7)>;
				drive-push-pull;
			};

			/omit-if-no-ref/ uart8_de_pd15: uart8_de_pd15 {
				pinmux = <STM32_PINMUX('D', 15, AF8)>;
				drive-push-pull;
			};

			/omit-if-no-ref/ uart9_de_pd13: uart9_de_pd13 {
				pinmux = <STM32_PINMUX('D', 13, AF11)>;
				drive-push-pull;
			};

			/* UART_RTS / USART_RTS / LPUART_RTS */

			/omit-if-no-ref/ usart10_rts_pg14: usart10_rts_pg14 {
				pinmux = <STM32_PINMUX('G', 14, AF6)>;
				drive-push-pull;
			};

			/omit-if-no-ref/ lpuart1_rts_pa12: lpuart1_rts_pa12 {
				pinmux = <STM32_PINMUX('A', 12, AF3)>;
				drive-push-pull;
			};

			/omit-if-no-ref/ usart1_rts_pa12: usart1_rts_pa12 {
				pinmux = <STM32_PINMUX('A', 12, AF7)>;
				drive-push-pull;
			};

			/omit-if-no-ref/ usart11_rts_pc1: usart11_rts_pc1 {
				pinmux = <STM32_PINMUX('C', 1, AF7)>;
				drive-push-pull;
			};

			/omit-if-no-ref/ usart11_rts_pg11: usart11_rts_pg11 {
				pinmux = <STM32_PINMUX('G', 11, AF7)>;
				drive-push-pull;
			};

			/omit-if-no-ref/ usart2_rts_pa1: usart2_rts_pa1 {
				pinmux = <STM32_PINMUX('A', 1, AF7)>;
				drive-push-pull;
			};

			/omit-if-no-ref/ uart12_rts_pc5: uart12_rts_pc5 {
				pinmux = <STM32_PINMUX('C', 5, AF7)>;
				drive-push-pull;
			};

			/omit-if-no-ref/ usart2_rts_pd4: usart2_rts_pd4 {
				pinmux = <STM32_PINMUX('D', 4, AF7)>;
				drive-push-pull;
			};

			/omit-if-no-ref/ uart12_rts_pe7: uart12_rts_pe7 {
				pinmux = <STM32_PINMUX('E', 7, AF6)>;
				drive-push-pull;
			};

			/omit-if-no-ref/ usart3_rts_pb14: usart3_rts_pb14 {
				pinmux = <STM32_PINMUX('B', 14, AF7)>;
				drive-push-pull;
			};

			/omit-if-no-ref/ usart3_rts_pd12: usart3_rts_pd12 {
				pinmux = <STM32_PINMUX('D', 12, AF7)>;
				drive-push-pull;
			};

			/omit-if-no-ref/ uart4_rts_pa15: uart4_rts_pa15 {
				pinmux = <STM32_PINMUX('A', 15, AF8)>;
				drive-push-pull;
			};

			/omit-if-no-ref/ uart4_rts_pb14: uart4_rts_pb14 {
				pinmux = <STM32_PINMUX('B', 14, AF8)>;
				drive-push-pull;
			};

			/omit-if-no-ref/ uart5_rts_pc8: uart5_rts_pc8 {
				pinmux = <STM32_PINMUX('C', 8, AF8)>;
				drive-push-pull;
			};

			/omit-if-no-ref/ usart6_rts_pg8: usart6_rts_pg8 {
				pinmux = <STM32_PINMUX('G', 8, AF7)>;
				drive-push-pull;
			};

			/omit-if-no-ref/ usart6_rts_pg12: usart6_rts_pg12 {
				pinmux = <STM32_PINMUX('G', 12, AF7)>;
				drive-push-pull;
			};

			/omit-if-no-ref/ uart7_rts_pe9: uart7_rts_pe9 {
				pinmux = <STM32_PINMUX('E', 9, AF7)>;
				drive-push-pull;
			};

			/omit-if-no-ref/ uart7_rts_pf8: uart7_rts_pf8 {
				pinmux = <STM32_PINMUX('F', 8, AF7)>;
				drive-push-pull;
			};

			/omit-if-no-ref/ uart8_rts_pd15: uart8_rts_pd15 {
				pinmux = <STM32_PINMUX('D', 15, AF8)>;
				drive-push-pull;
			};

			/omit-if-no-ref/ uart9_rts_pd13: uart9_rts_pd13 {
				pinmux = <STM32_PINMUX('D', 13, AF11)>;
				drive-push-pull;
			};

			/* UART_RX / USART_RX / LPUART_RX */

			/omit-if-no-ref/ usart10_rx_pe2: usart10_rx_pe2 {
				pinmux = <STM32_PINMUX('E', 2, AF7)>;
			};

			/omit-if-no-ref/ usart10_rx_pg11: usart10_rx_pg11 {
				pinmux = <STM32_PINMUX('G', 11, AF6)>;
			};

			/omit-if-no-ref/ usart11_rx_pa7: usart11_rx_pa7 {
				pinmux = <STM32_PINMUX('A', 7, AF7)>;
			};

			/omit-if-no-ref/ lpuart1_rx_pa10: lpuart1_rx_pa10 {
				pinmux = <STM32_PINMUX('A', 10, AF3)>;
			};

			/omit-if-no-ref/ usart1_rx_pa10: usart1_rx_pa10 {
				pinmux = <STM32_PINMUX('A', 10, AF7)>;
			};

			/omit-if-no-ref/ lpuart1_rx_pb7: lpuart1_rx_pb7 {
				pinmux = <STM32_PINMUX('B', 7, AF8)>;
			};

			/omit-if-no-ref/ usart1_rx_pb7: usart1_rx_pb7 {
				pinmux = <STM32_PINMUX('B', 7, AF7)>;
			};

			/omit-if-no-ref/ usart1_rx_pb15: usart1_rx_pb15 {
				pinmux = <STM32_PINMUX('B', 15, AF4)>;
			};

			/omit-if-no-ref/ usart11_rx_pf4: usart11_rx_pf4 {
				pinmux = <STM32_PINMUX('F', 4, AF7)>;
			};

			/omit-if-no-ref/ usart2_rx_pa3: usart2_rx_pa3 {
				pinmux = <STM32_PINMUX('A', 3, AF7)>;
			};

			/omit-if-no-ref/ usart2_rx_pd6: usart2_rx_pd6 {
				pinmux = <STM32_PINMUX('D', 6, AF7)>;
			};

			/omit-if-no-ref/ uart12_rx_pe9: uart12_rx_pe9 {
				pinmux = <STM32_PINMUX('E', 9, AF6)>;
			};

			/omit-if-no-ref/ uart12_rx_pf5: uart12_rx_pf5 {
				pinmux = <STM32_PINMUX('F', 5, AF6)>;
			};

			/omit-if-no-ref/ uart12_rx_pg2: uart12_rx_pg2 {
				pinmux = <STM32_PINMUX('G', 2, AF7)>;
			};

			/omit-if-no-ref/ usart3_rx_pb11: usart3_rx_pb11 {
				pinmux = <STM32_PINMUX('B', 11, AF7)>;
			};

			/omit-if-no-ref/ usart3_rx_pc4: usart3_rx_pc4 {
				pinmux = <STM32_PINMUX('C', 4, AF7)>;
			};

			/omit-if-no-ref/ usart3_rx_pc11: usart3_rx_pc11 {
				pinmux = <STM32_PINMUX('C', 11, AF7)>;
			};

			/omit-if-no-ref/ usart3_rx_pd9: usart3_rx_pd9 {
				pinmux = <STM32_PINMUX('D', 9, AF7)>;
			};

			/omit-if-no-ref/ uart4_rx_pa1: uart4_rx_pa1 {
				pinmux = <STM32_PINMUX('A', 1, AF8)>;
			};

			/omit-if-no-ref/ uart4_rx_pa11: uart4_rx_pa11 {
				pinmux = <STM32_PINMUX('A', 11, AF6)>;
			};

			/omit-if-no-ref/ uart4_rx_pb8: uart4_rx_pb8 {
				pinmux = <STM32_PINMUX('B', 8, AF8)>;
			};

			/omit-if-no-ref/ uart4_rx_pc11: uart4_rx_pc11 {
				pinmux = <STM32_PINMUX('C', 11, AF8)>;
			};

			/omit-if-no-ref/ uart4_rx_pd0: uart4_rx_pd0 {
				pinmux = <STM32_PINMUX('D', 0, AF8)>;
			};

			/omit-if-no-ref/ uart4_rx_pd11: uart4_rx_pd11 {
				pinmux = <STM32_PINMUX('D', 11, AF8)>;
			};

			/omit-if-no-ref/ uart4_rx_ph14: uart4_rx_ph14 {
				pinmux = <STM32_PINMUX('H', 14, AF8)>;
			};

			/omit-if-no-ref/ uart5_rx_pb5: uart5_rx_pb5 {
				pinmux = <STM32_PINMUX('B', 5, AF14)>;
			};

			/omit-if-no-ref/ uart5_rx_pb12: uart5_rx_pb12 {
				pinmux = <STM32_PINMUX('B', 12, AF14)>;
			};

			/omit-if-no-ref/ uart5_rx_pb15: uart5_rx_pb15 {
				pinmux = <STM32_PINMUX('B', 15, AF14)>;
			};

			/omit-if-no-ref/ uart5_rx_pd2: uart5_rx_pd2 {
				pinmux = <STM32_PINMUX('D', 2, AF8)>;
			};

			/omit-if-no-ref/ usart6_rx_pc7: usart6_rx_pc7 {
				pinmux = <STM32_PINMUX('C', 7, AF7)>;
			};

			/omit-if-no-ref/ usart6_rx_pg9: usart6_rx_pg9 {
				pinmux = <STM32_PINMUX('G', 9, AF7)>;
			};

			/omit-if-no-ref/ uart7_rx_pa8: uart7_rx_pa8 {
				pinmux = <STM32_PINMUX('A', 8, AF11)>;
			};

			/omit-if-no-ref/ uart7_rx_pb3: uart7_rx_pb3 {
				pinmux = <STM32_PINMUX('B', 3, AF11)>;
			};

			/omit-if-no-ref/ uart7_rx_pe7: uart7_rx_pe7 {
				pinmux = <STM32_PINMUX('E', 7, AF7)>;
			};

			/omit-if-no-ref/ uart7_rx_pf6: uart7_rx_pf6 {
				pinmux = <STM32_PINMUX('F', 6, AF7)>;
			};

			/omit-if-no-ref/ uart8_rx_pe0: uart8_rx_pe0 {
				pinmux = <STM32_PINMUX('E', 0, AF8)>;
			};

			/omit-if-no-ref/ uart9_rx_pd14: uart9_rx_pd14 {
				pinmux = <STM32_PINMUX('D', 14, AF11)>;
			};

			/omit-if-no-ref/ uart9_rx_pg0: uart9_rx_pg0 {
				pinmux = <STM32_PINMUX('G', 0, AF11)>;
			};

			/* UART_TX / USART_TX / LPUART_TX */

			/omit-if-no-ref/ usart10_tx_pe3: usart10_tx_pe3 {
				pinmux = <STM32_PINMUX('E', 3, AF7)>;
				bias-pull-up;
			};

			/omit-if-no-ref/ usart10_tx_pg12: usart10_tx_pg12 {
				pinmux = <STM32_PINMUX('G', 12, AF6)>;
				bias-pull-up;
			};

			/omit-if-no-ref/ usart11_tx_pa6: usart11_tx_pa6 {
				pinmux = <STM32_PINMUX('A', 6, AF7)>;
				bias-pull-up;
			};

			/omit-if-no-ref/ lpuart1_tx_pa9: lpuart1_tx_pa9 {
				pinmux = <STM32_PINMUX('A', 9, AF3)>;
				bias-pull-up;
			};

			/omit-if-no-ref/ usart1_tx_pa9: usart1_tx_pa9 {
				pinmux = <STM32_PINMUX('A', 9, AF7)>;
				bias-pull-up;
			};

			/omit-if-no-ref/ lpuart1_tx_pb6: lpuart1_tx_pb6 {
				pinmux = <STM32_PINMUX('B', 6, AF8)>;
				bias-pull-up;
			};

			/omit-if-no-ref/ usart1_tx_pb6: usart1_tx_pb6 {
				pinmux = <STM32_PINMUX('B', 6, AF7)>;
				bias-pull-up;
			};

			/omit-if-no-ref/ usart1_tx_pb14: usart1_tx_pb14 {
				pinmux = <STM32_PINMUX('B', 14, AF4)>;
				bias-pull-up;
			};

			/omit-if-no-ref/ usart11_tx_pf3: usart11_tx_pf3 {
				pinmux = <STM32_PINMUX('F', 3, AF7)>;
				bias-pull-up;
			};

			/omit-if-no-ref/ usart2_tx_pa2: usart2_tx_pa2 {
				pinmux = <STM32_PINMUX('A', 2, AF7)>;
				bias-pull-up;
			};

			/omit-if-no-ref/ usart2_tx_pd5: usart2_tx_pd5 {
				pinmux = <STM32_PINMUX('D', 5, AF7)>;
				bias-pull-up;
			};

			/omit-if-no-ref/ uart12_tx_pe10: uart12_tx_pe10 {
				pinmux = <STM32_PINMUX('E', 10, AF6)>;
				bias-pull-up;
			};

			/omit-if-no-ref/ uart12_tx_pf2: uart12_tx_pf2 {
				pinmux = <STM32_PINMUX('F', 2, AF6)>;
				bias-pull-up;
			};

			/omit-if-no-ref/ uart12_tx_pg3: uart12_tx_pg3 {
				pinmux = <STM32_PINMUX('G', 3, AF7)>;
				bias-pull-up;
			};

			/omit-if-no-ref/ usart3_tx_pb10: usart3_tx_pb10 {
				pinmux = <STM32_PINMUX('B', 10, AF7)>;
				bias-pull-up;
			};

			/omit-if-no-ref/ usart3_tx_pc10: usart3_tx_pc10 {
				pinmux = <STM32_PINMUX('C', 10, AF7)>;
				bias-pull-up;
			};

			/omit-if-no-ref/ usart3_tx_pd8: usart3_tx_pd8 {
				pinmux = <STM32_PINMUX('D', 8, AF7)>;
				bias-pull-up;
			};

			/omit-if-no-ref/ uart4_tx_pa0: uart4_tx_pa0 {
				pinmux = <STM32_PINMUX('A', 0, AF8)>;
				bias-pull-up;
			};

			/omit-if-no-ref/ uart4_tx_pa12: uart4_tx_pa12 {
				pinmux = <STM32_PINMUX('A', 12, AF6)>;
				bias-pull-up;
			};

			/omit-if-no-ref/ uart4_tx_pb9: uart4_tx_pb9 {
				pinmux = <STM32_PINMUX('B', 9, AF8)>;
				bias-pull-up;
			};

			/omit-if-no-ref/ uart4_tx_pc10: uart4_tx_pc10 {
				pinmux = <STM32_PINMUX('C', 10, AF8)>;
				bias-pull-up;
			};

			/omit-if-no-ref/ uart4_tx_pd1: uart4_tx_pd1 {
				pinmux = <STM32_PINMUX('D', 1, AF8)>;
				bias-pull-up;
			};

			/omit-if-no-ref/ uart4_tx_pd12: uart4_tx_pd12 {
				pinmux = <STM32_PINMUX('D', 12, AF8)>;
				bias-pull-up;
			};

			/omit-if-no-ref/ uart4_tx_ph13: uart4_tx_ph13 {
				pinmux = <STM32_PINMUX('H', 13, AF8)>;
				bias-pull-up;
			};

			/omit-if-no-ref/ uart5_tx_pb6: uart5_tx_pb6 {
				pinmux = <STM32_PINMUX('B', 6, AF14)>;
				bias-pull-up;
			};

			/omit-if-no-ref/ uart5_tx_pb13: uart5_tx_pb13 {
				pinmux = <STM32_PINMUX('B', 13, AF14)>;
				bias-pull-up;
			};

			/omit-if-no-ref/ uart5_tx_pc12: uart5_tx_pc12 {
				pinmux = <STM32_PINMUX('C', 12, AF8)>;
				bias-pull-up;
			};

			/omit-if-no-ref/ usart6_tx_pc6: usart6_tx_pc6 {
				pinmux = <STM32_PINMUX('C', 6, AF7)>;
				bias-pull-up;
			};

			/omit-if-no-ref/ usart6_tx_pg14: usart6_tx_pg14 {
				pinmux = <STM32_PINMUX('G', 14, AF7)>;
				bias-pull-up;
			};

			/omit-if-no-ref/ uart7_tx_pa15: uart7_tx_pa15 {
				pinmux = <STM32_PINMUX('A', 15, AF11)>;
				bias-pull-up;
			};

			/omit-if-no-ref/ uart7_tx_pb4: uart7_tx_pb4 {
				pinmux = <STM32_PINMUX('B', 4, AF11)>;
				bias-pull-up;
			};

			/omit-if-no-ref/ uart7_tx_pe8: uart7_tx_pe8 {
				pinmux = <STM32_PINMUX('E', 8, AF7)>;
				bias-pull-up;
			};

			/omit-if-no-ref/ uart7_tx_pf7: uart7_tx_pf7 {
				pinmux = <STM32_PINMUX('F', 7, AF7)>;
				bias-pull-up;
			};

			/omit-if-no-ref/ uart8_tx_pe1: uart8_tx_pe1 {
				pinmux = <STM32_PINMUX('E', 1, AF8)>;
				bias-pull-up;
			};

			/omit-if-no-ref/ uart8_tx_pe2: uart8_tx_pe2 {
				pinmux = <STM32_PINMUX('E', 2, AF8)>;
				bias-pull-up;
			};

			/omit-if-no-ref/ uart8_tx_ph13: uart8_tx_ph13 {
				pinmux = <STM32_PINMUX('H', 13, AF7)>;
				bias-pull-up;
			};

			/omit-if-no-ref/ uart9_tx_pd15: uart9_tx_pd15 {
				pinmux = <STM32_PINMUX('D', 15, AF11)>;
				bias-pull-up;
			};

			/omit-if-no-ref/ uart9_tx_pg1: uart9_tx_pg1 {
				pinmux = <STM32_PINMUX('G', 1, AF11)>;
				bias-pull-up;
			};

			/* UCPD */

			/omit-if-no-ref/ ucpd1_cc1_pb13: ucpd1_cc1_pb13 {
				pinmux = <STM32_PINMUX('B', 13, ANALOG)>;
			};

			/omit-if-no-ref/ ucpd1_cc2_pb14: ucpd1_cc2_pb14 {
				pinmux = <STM32_PINMUX('B', 14, ANALOG)>;
			};

			/* USB */

			/omit-if-no-ref/ usb_dm_pa11: usb_dm_pa11 {
				pinmux = <STM32_PINMUX('A', 11, AF10)>;
			};

			/omit-if-no-ref/ usb_dp_pa12: usb_dp_pa12 {
				pinmux = <STM32_PINMUX('A', 12, AF10)>;
			};

		};
	};
};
